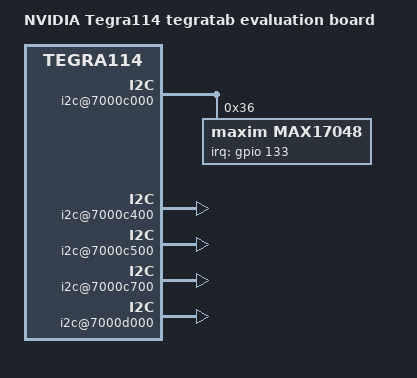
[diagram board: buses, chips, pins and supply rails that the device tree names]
/*
 * Copyright (c) 2013-2014, NVIDIA CORPORATION.  All rights reserved.
 *
 * This program is free software; you can redistribute it and/or modify it
 * under the terms and conditions of the GNU General Public License,
 * version 2, as published by the Free Software Foundation.
 *
 * This program is distributed in the hope it will be useful, but WITHOUT
 * ANY WARRANTY; without even the implied warranty of MERCHANTABILITY or
 * FITNESS FOR A PARTICULAR PURPOSE.  See the GNU General Public License for
 * more details.
 *
 * You should have received a copy of the GNU General Public License
 * along with this program.  If not, see <http://www.gnu.org/licenses/>.
 */

/include/ "tegra114.dtsi"

/ {
	model = "NVIDIA Tegra114 tegratab evaluation board";
	compatible = "nvidia,tegratab", "nvidia,tegra114";

	gpio@6000d000 {
		status = "okay";
	};

	interrupt-controller@50041000 {
		status = "okay";
	};

	pinmux {
		pinctrl-names = "default";
		pinctrl-0 = <&state_default>;

		state_default: pinmux {
			clk1_out_pw4 {
				nvidia,pins = "clk1_out_pw4";
				nvidia,function = "extperiph1";
				nvidia,pull = <0>;
				nvidia,tristate = <0>;
				nvidia,enable-input = <0>;
			};
			dap1_din_pn1 {
				nvidia,pins = "dap1_din_pn1";
				nvidia,function = "i2s0";
				nvidia,pull = <0>;
				nvidia,tristate = <1>;
				nvidia,enable-input = <1>;
			};
			dap1_dout_pn2 {
				nvidia,pins = "dap1_dout_pn2",
						"dap1_fs_pn0",
						"dap1_sclk_pn3";
				nvidia,function = "i2s0";
				nvidia,pull = <0>;
				nvidia,tristate = <0>;
				nvidia,enable-input = <1>;
			};
			dap2_din_pa4 {
				nvidia,pins = "dap2_din_pa4";
				nvidia,function = "i2s1";
				nvidia,pull = <0>;
				nvidia,tristate = <1>;
				nvidia,enable-input = <1>;
			};
			dap2_dout_pa5 {
				nvidia,pins = "dap2_dout_pa5",
						"dap2_fs_pa2",
						"dap2_sclk_pa3";
				nvidia,function = "i2s1";
				nvidia,pull = <0>;
				nvidia,tristate = <0>;
				nvidia,enable-input = <1>;
			};
			dap4_din_pp5 {
				nvidia,pins = "dap4_din_pp5",
						"dap4_dout_pp6",
						"dap4_fs_pp4",
						"dap4_sclk_pp7";
				nvidia,function = "i2s3";
				nvidia,pull = <0>;
				nvidia,tristate = <0>;
				nvidia,enable-input = <1>;
			};
			dvfs_pwm_px0 {
				nvidia,pins = "dvfs_pwm_px0",
						"dvfs_clk_px2";
				nvidia,function = "cldvfs";
				nvidia,pull = <0>;
				nvidia,tristate = <0>;
				nvidia,enable-input = <0>;
			};
			ulpi_clk_py0 {
				nvidia,pins = "ulpi_clk_py0",
						"ulpi_data0_po1",
						"ulpi_data1_po2",
						"ulpi_data2_po3",
						"ulpi_data3_po4",
						"ulpi_data4_po5",
						"ulpi_data5_po6",
						"ulpi_data6_po7",
						"ulpi_data7_po0";
				nvidia,function = "ulpi";
				nvidia,pull = <0>;
				nvidia,tristate = <0>;
				nvidia,enable-input = <1>;
			};
			ulpi_dir_py1 {
				nvidia,pins = "ulpi_dir_py1",
						"ulpi_nxt_py2";
				nvidia,function = "ulpi";
				nvidia,pull = <0>;
				nvidia,tristate = <1>;
				nvidia,enable-input = <1>;
			};
			ulpi_stp_py3 {
				nvidia,pins = "ulpi_stp_py3";
				nvidia,function = "ulpi";
				nvidia,pull = <0>;
				nvidia,tristate = <0>;
				nvidia,enable-input = <0>;
			};
			cam_i2c_scl_pbb1 {
				nvidia,pins = "cam_i2c_scl_pbb1",
						"cam_i2c_sda_pbb2";
				nvidia,function = "i2c3";
				nvidia,pull = <0>;
				nvidia,tristate = <0>;
				nvidia,enable-input = <1>;
				nvidia,lock = <0>;
				nvidia,open-drain = <0>;
			};
			cam_mclk_pcc0 {
				nvidia,pins = "cam_mclk_pcc0",
						"pbb0";
				nvidia,function = "vi_alt3";
				nvidia,pull = <0>;
				nvidia,tristate = <0>;
				nvidia,enable-input = <0>;
				nvidia,lock = <0>;
			};
			gen2_i2c_scl_pt5 {
				nvidia,pins = "gen2_i2c_scl_pt5",
						"gen2_i2c_sda_pt6";
				nvidia,function = "i2c2";
				nvidia,pull = <0>;
				nvidia,tristate = <0>;
				nvidia,enable-input = <1>;
				nvidia,lock = <0>;
				nvidia,open-drain = <0>;
			};
			gmi_a16_pj7 {
				nvidia,pins = "gmi_a16_pj7";
				nvidia,function = "uartd";
				nvidia,pull = <0>;
				nvidia,tristate = <0>;
				nvidia,enable-input = <0>;
			};
			gmi_a17_pb0 {
				nvidia,pins = "gmi_a17_pb0",
						"gmi_a18_pb1";
				nvidia,function = "uartd";
				nvidia,pull = <0>;
				nvidia,tristate = <1>;
				nvidia,enable-input = <1>;
			};
			gmi_a19_pk7 {
				nvidia,pins = "gmi_a19_pk7";
				nvidia,function = "uartd";
				nvidia,pull = <0>;
				nvidia,tristate = <0>;
				nvidia,enable-input = <0>;
			};
			gmi_ad5_pg5 {
				nvidia,pins = "gmi_ad5_pg5",
						"gmi_cs6_n_pi3",
						"gmi_wr_n_pi0";
				nvidia,function = "spi4";
				nvidia,pull = <0>;
				nvidia,tristate = <0>;
				nvidia,enable-input = <1>;
			};
			gmi_ad6_pg6 {
				nvidia,pins = "gmi_ad6_pg6",
						"gmi_ad7_pg7";
				nvidia,function = "spi4";
				nvidia,pull = <2>;
				nvidia,tristate = <0>;
				nvidia,enable-input = <1>;
			};
			gmi_ad12_ph4 {
				nvidia,pins = "gmi_ad12_ph4";
				nvidia,function = "rsvd4";
				nvidia,pull = <0>;
				nvidia,tristate = <0>;
				nvidia,enable-input = <0>;
			};
			gmi_ad9_ph1 {
				nvidia,pins = "gmi_ad9_ph1";
				nvidia,function = "pwm1";
				nvidia,pull = <0>;
				nvidia,tristate = <0>;
				nvidia,enable-input = <0>;
			};
			gmi_cs1_n_pj2 {
				nvidia,pins = "gmi_cs1_n_pj2",
						"gmi_oe_n_pi1";
				nvidia,function = "soc";
				nvidia,pull = <0>;
				nvidia,tristate = <1>;
				nvidia,enable-input = <1>;
			};
			clk2_out_pw5 {
				nvidia,pins = "clk2_out_pw5";
				nvidia,function = "extperiph2";
				nvidia,pull = <0>;
				nvidia,tristate = <0>;
				nvidia,enable-input = <0>;
			};
			sdmmc1_clk_pz0 {
				nvidia,pins = "sdmmc1_clk_pz0";
				nvidia,function = "sdmmc1";
				nvidia,pull = <0>;
				nvidia,tristate = <0>;
				nvidia,enable-input = <1>;
			};
			sdmmc1_cmd_pz1 {
				nvidia,pins = "sdmmc1_cmd_pz1",
						"sdmmc1_dat0_py7",
						"sdmmc1_dat1_py6",
						"sdmmc1_dat2_py5",
						"sdmmc1_dat3_py4";
				nvidia,function = "sdmmc1";
				nvidia,pull = <2>;
				nvidia,tristate = <0>;
				nvidia,enable-input = <1>;
			};
			sdmmc1_wp_n_pv3 {
				nvidia,pins = "sdmmc1_wp_n_pv3";
				nvidia,function = "spi4";
				nvidia,pull = <2>;
				nvidia,tristate = <0>;
				nvidia,enable-input = <0>;
			};
			sdmmc3_clk_pa6 {
				nvidia,pins = "sdmmc3_clk_pa6";
				nvidia,function = "sdmmc3";
				nvidia,pull = <0>;
				nvidia,tristate = <0>;
				nvidia,enable-input = <1>;
			};
			sdmmc3_cmd_pa7 {
				nvidia,pins = "sdmmc3_cmd_pa7",
						"sdmmc3_dat0_pb7",
						"sdmmc3_dat1_pb6",
						"sdmmc3_dat2_pb5",
						"sdmmc3_dat3_pb4",
						"kb_col4_pq4",
						"sdmmc3_clk_lb_out_pee4",
						"sdmmc3_clk_lb_in_pee5";
				nvidia,function = "sdmmc3";
				nvidia,pull = <2>;
				nvidia,tristate = <0>;
				nvidia,enable-input = <1>;
			};
			sdmmc4_clk_pcc4 {
				nvidia,pins = "sdmmc4_clk_pcc4";
				nvidia,function = "sdmmc4";
				nvidia,pull = <0>;
				nvidia,tristate = <0>;
				nvidia,enable-input = <1>;
			};
			sdmmc4_cmd_pt7 {
				nvidia,pins = "sdmmc4_cmd_pt7",
						"sdmmc4_dat0_paa0",
						"sdmmc4_dat1_paa1",
						"sdmmc4_dat2_paa2",
						"sdmmc4_dat3_paa3",
						"sdmmc4_dat4_paa4",
						"sdmmc4_dat5_paa5",
						"sdmmc4_dat6_paa6",
						"sdmmc4_dat7_paa7";
				nvidia,function = "sdmmc4";
				nvidia,pull = <2>;
				nvidia,tristate = <0>;
				nvidia,enable-input = <1>;
			};
			clk_32k_out_pa0 {
				nvidia,pins = "clk_32k_out_pa0";
				nvidia,function = "blink";
				nvidia,pull = <0>;
				nvidia,tristate = <0>;
				nvidia,enable-input = <0>;
			};
			kb_col0_pq0 {
				nvidia,pins = "kb_col0_pq0",
						"kb_col1_pq1",
						"kb_col2_pq2",
						"kb_row0_pr0",
						"kb_row1_pr1",
						"kb_row2_pr2";
				nvidia,function = "kbc";
				nvidia,pull = <2>;
				nvidia,tristate = <0>;
				nvidia,enable-input = <1>;
			};
			dap3_din_pp1 {
				nvidia,pins = "dap3_din_pp1",
						"dap3_sclk_pp3";
				nvidia,function = "displayb";
				nvidia,pull = <0>;
				nvidia,tristate = <1>;
				nvidia,enable-input = <0>;
			};
			pv0 {
				nvidia,pins = "pv0";
				nvidia,function = "rsvd4";
				nvidia,pull = <0>;
				nvidia,tristate = <1>;
				nvidia,enable-input = <0>;
			};
			kb_row7_pr7 {
				nvidia,pins = "kb_row7_pr7";
				nvidia,function = "rsvd2";
				nvidia,pull = <2>;
				nvidia,tristate = <0>;
				nvidia,enable-input = <1>;
			};
			kb_row10_ps2 {
				nvidia,pins = "kb_row10_ps2";
				nvidia,function = "uarta";
				nvidia,pull = <0>;
				nvidia,tristate = <1>;
				nvidia,enable-input = <1>;
			};
			kb_row9_ps1 {
				nvidia,pins = "kb_row9_ps1";
				nvidia,function = "uarta";
				nvidia,pull = <0>;
				nvidia,tristate = <0>;
				nvidia,enable-input = <0>;
			};
			pwr_i2c_scl_pz6 {
				nvidia,pins = "pwr_i2c_scl_pz6",
						"pwr_i2c_sda_pz7";
				nvidia,function = "i2cpwr";
				nvidia,pull = <0>;
				nvidia,tristate = <0>;
				nvidia,enable-input = <1>;
				nvidia,lock = <0>;
				nvidia,open-drain = <0>;
			};
			sys_clk_req_pz5 {
				nvidia,pins = "sys_clk_req_pz5";
				nvidia,function = "sysclk";
				nvidia,pull = <0>;
				nvidia,tristate = <0>;
				nvidia,enable-input = <0>;
			};
			core_pwr_req {
				nvidia,pins = "core_pwr_req";
				nvidia,function = "pwron";
				nvidia,pull = <0>;
				nvidia,tristate = <0>;
				nvidia,enable-input = <0>;
			};
			cpu_pwr_req {
				nvidia,pins = "cpu_pwr_req";
				nvidia,function = "cpu";
				nvidia,pull = <0>;
				nvidia,tristate = <0>;
				nvidia,enable-input = <0>;
			};
			pwr_int_n {
				nvidia,pins = "pwr_int_n";
				nvidia,function = "pmi";
				nvidia,pull = <0>;
				nvidia,tristate = <1>;
				nvidia,enable-input = <1>;
			};
			reset_out_n {
				nvidia,pins = "reset_out_n";
				nvidia,function = "reset_out_n";
				nvidia,pull = <0>;
				nvidia,tristate = <0>;
				nvidia,enable-input = <0>;
			};
			clk3_out_pee0 {
				nvidia,pins = "clk3_out_pee0";
				nvidia,function = "extperiph3";
				nvidia,pull = <0>;
				nvidia,tristate = <0>;
				nvidia,enable-input = <0>;
			};
			gen1_i2c_scl_pc4 {
				nvidia,pins = "gen1_i2c_scl_pc4",
						"gen1_i2c_sda_pc5";
				nvidia,function = "i2c1";
				nvidia,pull = <0>;
				nvidia,tristate = <0>;
				nvidia,enable-input = <1>;
				nvidia,lock = <0>;
				nvidia,open-drain = <0>;
			};
			uart2_cts_n_pj5 {
				nvidia,pins = "uart2_cts_n_pj5";
				nvidia,function = "uartb";
				nvidia,pull = <0>;
				nvidia,tristate = <1>;
				nvidia,enable-input = <1>;
			};
			uart2_rts_n_pj6 {
				nvidia,pins = "uart2_rts_n_pj6";
				nvidia,function = "uartb";
				nvidia,pull = <0>;
				nvidia,tristate = <0>;
				nvidia,enable-input = <0>;
			};
			uart2_rxd_pc3 {
				nvidia,pins = "uart2_rxd_pc3";
				nvidia,function = "irda";
				nvidia,pull = <0>;
				nvidia,tristate = <1>;
				nvidia,enable-input = <1>;
			};
			uart2_txd_pc2 {
				nvidia,pins = "uart2_txd_pc2";
				nvidia,function = "irda";
				nvidia,pull = <0>;
				nvidia,tristate = <0>;
				nvidia,enable-input = <0>;
			};
			uart3_cts_n_pa1 {
				nvidia,pins = "uart3_cts_n_pa1",
						"uart3_rxd_pw7";
				nvidia,function = "uartc";
				nvidia,pull = <0>;
				nvidia,tristate = <1>;
				nvidia,enable-input = <1>;
			};
			uart3_rts_n_pc0 {
				nvidia,pins = "uart3_rts_n_pc0",
						"uart3_txd_pw6";
				nvidia,function = "uartc";
				nvidia,pull = <0>;
				nvidia,tristate = <0>;
				nvidia,enable-input = <0>;
			};
			owr {
				nvidia,pins = "owr";
				nvidia,function = "owr";
				nvidia,pull = <0>;
				nvidia,tristate = <0>;
				nvidia,enable-input = <1>;
			};
			hdmi_cec_pee3 {
				nvidia,pins = "hdmi_cec_pee3";
				nvidia,function = "cec";
				nvidia,pull = <0>;
				nvidia,tristate = <0>;
				nvidia,enable-input = <1>;
				nvidia,lock = <0>;
				nvidia,open-drain = <0>;
			};
			ddc_scl_pv4 {
				nvidia,pins = "ddc_scl_pv4",
						"ddc_sda_pv5";
				nvidia,function = "i2c4";
				nvidia,pull = <0>;
				nvidia,tristate = <0>;
				nvidia,enable-input = <1>;
				nvidia,lock = <0>;
				nvidia,rcv-sel = <1>;
			};
			spdif_in_pk6 {
				nvidia,pins = "spdif_in_pk6";
				nvidia,function = "usb";
				nvidia,pull = <2>;
				nvidia,tristate = <0>;
				nvidia,enable-input = <1>;
				nvidia,lock = <0>;
			};
			usb_vbus_en0_pn4 {
				nvidia,pins = "usb_vbus_en0_pn4";
				nvidia,function = "usb";
				nvidia,pull = <2>;
				nvidia,tristate = <0>;
				nvidia,enable-input = <1>;
				nvidia,lock = <0>;
				nvidia,open-drain = <1>;
			};
			gpio_x6_aud_px6 {
				nvidia,pins = "gpio_x6_aud_px6";
				nvidia,function = "spi6";
				nvidia,pull = <2>;
				nvidia,tristate = <1>;
				nvidia,enable-input = <1>;
			};
			gpio_x4_aud_px4 {
				nvidia,pins = "gpio_x4_aud_px4",
						"gpio_x7_aud_px7";
				nvidia,function = "rsvd1";
				nvidia,pull = <1>;
				nvidia,tristate = <0>;
				nvidia,enable-input = <0>;
			};
			gpio_x5_aud_px5 {
				nvidia,pins = "gpio_x5_aud_px5";
				nvidia,function = "rsvd1";
				nvidia,pull = <2>;
				nvidia,tristate = <0>;
				nvidia,enable-input = <1>;
			};
			gpio_w2_aud_pw2 {
				nvidia,pins = "gpio_w2_aud_pw2";
				nvidia,function = "rsvd2";
				nvidia,pull = <2>;
				nvidia,tristate = <0>;
				nvidia,enable-input = <1>;
			};
			gpio_w3_aud_pw3 {
				nvidia,pins = "gpio_w3_aud_pw3";
				nvidia,function = "spi6";
				nvidia,pull = <2>;
				nvidia,tristate = <0>;
				nvidia,enable-input = <1>;
			};
			gpio_x1_aud_px1 {
				nvidia,pins = "gpio_x1_aud_px1";
				nvidia,function = "rsvd4";
				nvidia,pull = <1>;
				nvidia,tristate = <0>;
				nvidia,enable-input = <1>;
			};
			gpio_x3_aud_px3 {
				nvidia,pins = "gpio_x3_aud_px3";
				nvidia,function = "rsvd4";
				nvidia,pull = <2>;
				nvidia,tristate = <0>;
				nvidia,enable-input = <1>;
			};
			dap3_fs_pp0 {
				nvidia,pins = "dap3_fs_pp0";
				nvidia,function = "i2s2";
				nvidia,pull = <1>;
				nvidia,tristate = <0>;
				nvidia,enable-input = <0>;
			};
			dap3_dout_pp2 {
				nvidia,pins = "dap3_dout_pp2";
				nvidia,function = "i2s2";
				nvidia,pull = <1>;
				nvidia,tristate = <0>;
				nvidia,enable-input = <0>;
			};
			pv1 {
				nvidia,pins = "pv1";
				nvidia,function = "rsvd1";
				nvidia,pull = <0>;
				nvidia,tristate = <0>;
				nvidia,enable-input = <1>;
			};
			pbb3 {
				nvidia,pins = "pbb3",
						"pbb5",
						"pbb6",
						"pbb7";
				nvidia,function = "rsvd4";
				nvidia,pull = <1>;
				nvidia,tristate = <0>;
				nvidia,enable-input = <0>;
			};
			pcc1 {
				nvidia,pins = "pcc1",
						"pcc2";
				nvidia,function = "rsvd4";
				nvidia,pull = <1>;
				nvidia,tristate = <0>;
				nvidia,enable-input = <1>;
			};
			gmi_ad0_pg0 {
				nvidia,pins = "gmi_ad0_pg0",
						"gmi_ad1_pg1";
				nvidia,function = "gmi";
				nvidia,pull = <0>;
				nvidia,tristate = <0>;
				nvidia,enable-input = <0>;
			};
			gmi_ad10_ph2 {
				nvidia,pins = "gmi_ad10_ph2",
						"gmi_ad11_ph3",
						"gmi_ad13_ph5",
						"gmi_ad8_ph0",
						"gmi_clk_pk1";
				nvidia,function = "gmi";
				nvidia,pull = <1>;
				nvidia,tristate = <0>;
				nvidia,enable-input = <0>;
			};
			gmi_ad2_pg2 {
				nvidia,pins = "gmi_ad2_pg2",
						"gmi_ad3_pg3";
				nvidia,function = "gmi";
				nvidia,pull = <0>;
				nvidia,tristate = <0>;
				nvidia,enable-input = <1>;
			};
			gmi_adv_n_pk0 {
				nvidia,pins = "gmi_adv_n_pk0",
						"gmi_cs0_n_pj0",
						"gmi_cs2_n_pk3",
						"gmi_cs4_n_pk2",
						"gmi_cs7_n_pi6",
						"gmi_dqs_p_pj3",
						"gmi_iordy_pi5",
						"gmi_wp_n_pc7";
				nvidia,function = "gmi";
				nvidia,pull = <2>;
				nvidia,tristate = <0>;
				nvidia,enable-input = <1>;
			};
			gmi_cs3_n_pk4 {
				nvidia,pins = "gmi_cs3_n_pk4";
				nvidia,function = "gmi";
				nvidia,pull = <2>;
				nvidia,tristate = <0>;
				nvidia,enable-input = <0>;
			};
			clk2_req_pcc5 {
				nvidia,pins = "clk2_req_pcc5";
				nvidia,function = "rsvd4";
				nvidia,pull = <0>;
				nvidia,tristate = <0>;
				nvidia,enable-input = <0>;
			};
			kb_col3_pq3 {
				nvidia,pins = "kb_col3_pq3",
						"kb_col6_pq6",
						"kb_col7_pq7";
				nvidia,function = "kbc";
				nvidia,pull = <2>;
				nvidia,tristate = <0>;
				nvidia,enable-input = <0>;
			};
			kb_col5_pq5 {
				nvidia,pins = "kb_col5_pq5";
				nvidia,function = "kbc";
				nvidia,pull = <2>;
				nvidia,tristate = <0>;
				nvidia,enable-input = <1>;
			};
			kb_row3_pr3 {
				nvidia,pins = "kb_row3_pr3",
						"kb_row4_pr4",
						"kb_row6_pr6",
						"kb_row8_ps0";
				nvidia,function = "kbc";
				nvidia,pull = <1>;
				nvidia,tristate = <0>;
				nvidia,enable-input = <1>;
			};
			clk3_req_pee1 {
				nvidia,pins = "clk3_req_pee1";
				nvidia,function = "rsvd4";
				nvidia,pull = <0>;
				nvidia,tristate = <0>;
				nvidia,enable-input = <0>;
			};
			pu4 {
				nvidia,pins = "pu4";
				nvidia,function = "displayb";
				nvidia,pull = <0>;
				nvidia,tristate = <0>;
				nvidia,enable-input = <0>;
			};
			pu5 {
				nvidia,pins = "pu5",
						"pu6";
				nvidia,function = "displayb";
				nvidia,pull = <0>;
				nvidia,tristate = <0>;
				nvidia,enable-input = <1>;
			};
			hdmi_int_pn7 {
				nvidia,pins = "hdmi_int_pn7";
				nvidia,function = "rsvd1";
				nvidia,pull = <1>;
				nvidia,tristate = <0>;
				nvidia,enable-input = <1>;
			};
			clk1_req_pee2 {
				nvidia,pins = "clk1_req_pee2",
						"usb_vbus_en1_pn5";
				nvidia,function = "rsvd4";
				nvidia,pull = <1>;
				nvidia,tristate = <1>;
				nvidia,enable-input = <0>;
			};

			drive_sdio1 {
				nvidia,pins = "drive_sdio1";
				nvidia,high-speed-mode = <1>;
				nvidia,schmitt = <0>;
				nvidia,low-power-mode = <3>;
				nvidia,pull-down-strength = <36>;
				nvidia,pull-up-strength = <20>;
				nvidia,slew-rate-rising = <2>;
				nvidia,slew-rate-falling = <2>;
			};
			drive_sdio3 {
				nvidia,pins = "drive_sdio3";
				nvidia,high-speed-mode = <1>;
				nvidia,schmitt = <0>;
				nvidia,low-power-mode = <3>;
				nvidia,pull-down-strength = <22>;
				nvidia,pull-up-strength = <36>;
				nvidia,slew-rate-rising = <0>;
				nvidia,slew-rate-falling = <0>;
			};
			drive_gma {
				nvidia,pins = "drive_gma";
				nvidia,high-speed-mode = <1>;
				nvidia,schmitt = <0>;
				nvidia,low-power-mode = <3>;
				nvidia,pull-down-strength = <2>;
				nvidia,pull-up-strength = <1>;
				nvidia,slew-rate-rising = <0>;
				nvidia,slew-rate-falling = <0>;
				nvidia,drive-type = <1>;
			};
		};
	};

	host1x {
		compatible = "nvidia,tegra114-host1x", "simple-bus";
		reg = <0x50000000 0x00024000>;
		interrupts = <0 65 0x04   /* mpcore syncpt */
			      0 67 0x04>; /* mpcore general */

		#address-cells = <1>;
		#size-cells = <1>;

		ranges = <0x54000000 0x54000000 0x01000000>;

		vi {
			compatible = "nvidia,tegra114-vi";
			reg = <0x54080000 0x00040000>;
		};

		epp {
			compatible = "nvidia,tegra114-epp";
			reg = <0x540c0000 0x00040000>;
		};

		isp {
			compatible = "nvidia,tegra114-isp";
			reg = <0x54100000 0x00040000>;
		};

		gr2d {
			compatible = "nvidia,tegra114-gr2d";
			reg = <0x54140000 0x00040000>;
		};

		gr3d {
			compatible = "nvidia,tegra114-gr3d";
			reg = <0x54180000 0x00040000>;
		};

		dc@54200000 {
			compatible = "nvidia,tegra114-dc";
			reg = <0x54200000 0x00040000>;
			interrupts = <0 73 0x04>;
			status = "disabled";

			rgb {
				status = "disabled";
			};
		};

		dc@54240000 {
			compatible = "nvidia,tegra114-dc";
			reg = <0x54240000 0x00040000>;
			interrupts = <0 74 0x04>;
			status = "disabled";

			rgb {
				status = "disabled";
			};
		};

		hdmi {
			compatible = "nvidia,tegra114-hdmi";
			reg = <0x54280000 0x00040000>;
			interrupts = <0 75 0x04>;
			status = "disabled";
		};

		tvo {
			compatible = "nvidia,tegra114-tvo";
			reg = <0x542c0000 0x00040000>;
			interrupts = <0 76 0x04>;
			status = "disabled";
		};

		dsi {
			compatible = "nvidia,tegra114-dsi";
			reg = <0x54300000 0x00040000>;
			status = "disabled";
		};

		msenc {
			compatible = "nvidia,tegra114-msenc";
			reg = <0x544c0000 0x00040000>;
		};

		tsec {
			compatible = "nvidia,tegra114-tsec";
			reg = <0x54500000 0x00040000>;
		};
	};

	/* GEN1 */
	i2c@7000c000 {
		status = "okay";

		max17048@36 {
			compatible = "maxim,max17048";
			reg = <0x36>;
			interrupt-parent = <&gpio>;
			interrupts = <133 0x04>;	/* gpio PQ5 */
			alert-threshold = <1>;		/* 1% SOC */
			one-percent-alerts = <1>;
			valert-max = <5100>;		/* not use */
			valert-min = <3240>;		/* 3.24V */
			vreset-threshold = <2400>;
			vreset-disable = <1>;		/* not use */
			hib-threshold = <48>;		/* 9.984%/hr */
			hib-active-threshold = <128>;	/* 160mV */
			bits = <18>;
			rcomp = <57>;
			rcomp-seg = <0x0200>;
			soccheck-a = <119>;
			soccheck-b = <121>;
			ocvtest = <55952>;
			data-tbl = <0x98 0x80 0xB3 0x50 0xB7 0x90 0xB9 0x00
				0xBA 0x70 0xBC 0x10 0xBC 0x50 0xBC 0xA0
				0xBD 0x20 0xBE 0x30 0xBF 0x40 0xC2 0xF0
				0xC4 0x20 0xC7 0xE0 0xCB 0xF0 0xD0 0x90
				0x00 0x40 0x06 0x70 0x0E 0x50 0x12 0x00
				0x18 0xD0 0x33 0x10 0x31 0x40 0x35 0xD0
				0x18 0xD0 0x19 0x00 0x0B 0xF0 0x0C 0x10
				0x0D 0x10 0x07 0x90 0x08 0x00 0x08 0x00>;
		};
	};

	/* GEN2 */
	i2c@7000c400 {
		status = "okay";
	};

	/* CAM */
	i2c@7000c500 {
		status = "okay";
	};

	/* DDC */
	i2c@7000c700 {
		status = "okay";
	};

	/* PWR */
	i2c@7000d000 {
		status = "okay";
	};

	memory-controller@7001b000 {
		nvidia,use-ram-code = <1>;
		status = "okay";
		ram-code@0 { /* P1640_Micron_1GB_MT41K128M16-125 */
			#address-cells = <1>;
			#size-cells = <0>;
			nvidia,ram-code = <0>;
			emc-table@12750 {
				compatible = "nvidia,tegra11-emc-table";
				reg = <12750>;
				clock-frequency = <12750>;
				nvidia,revision = <0x42>;
				nvidia,emc-min-mv = <900>;
				nvidia,source = "pll_p";
				nvidia,src-sel-reg = <0x4400003e>;
				nvidia,burst-regs-num = <100>;
				nvidia,emc-trimmers-num = <30>;
				nvidia,burst-up-down-regs-num = <11>;
				nvidia,emc-registers = <0x00000000 0x00000003
						0x00000000 0x00000000 0x00000000 0x00000004
						0x0000000a 0x00000003 0x0000000b 0x00000000
						0x00000000 0x00000003 0x00000001 0x00000000
						0x00000005 0x0000000f 0x00000006 0x00010000
						0x00000000 0x00000004 0x0000000f 0x00000060
						0x00000000 0x00000018 0x00000002 0x00000002
						0x00000001 0x00000000 0x00000007 0x0000000f
						0x00000005 0x00000005 0x00000004 0x00000004
						0x00000004 0x00000004 0x00000000 0x00000004
						0x00000005 0x00000064 0x00000005 0x00000020
						0x00000000 0x0000aa88 0x002c00a0 0x00008000
						0x00058000 0x00058000 0x00058000 0x00058000
						0x00000000 0x00000000 0x00000000 0x00000000
						0x00000000 0x00000000 0x00000000 0x00000000
						0x001112a0 0x00000000 0x0000a11c 0x00000000
						0x77ffc085 0x81f1f108 0x03037504 0x0000003f
						0x0000003f 0x00000007 0x02000000 0x00000802
						0x00000000 0x00000042 0x000c000c 0x000c000c
						0x00000000 0x00000000 0x00000000 0x00000000
						0x800001c5 0x1f7df7df 0x0000001f 0x40040001
						0x8000003f 0x00000001 0x00000001 0x00000002
						0x00000000 0x00000001 0x00000001 0x00000002
						0x00000008 0x00000002 0x00000001 0x00000003
						0x00000006 0x06030102 0x000a0402 0x77e30303
						0x001f0000 0x00040320>;
				nvidia,emc-trimmers-0 = <0x00000000 0x00000006
						0x00000006 0x00000004 0x00000004 0x00058000
						0x00000009 0x00000000 0x0000000d 0x00249249
						0x20820800 0x00058000 0xa0f10f0f 0x00000000
						0x00000c0c 0x00000000 0x00000000 0x00000000
						0x00058000 0x00058000 0x00058000 0x00058000
						0x00058000 0x00058000 0x00000000 0x00000000
						0x00000000 0x00000000 0x00000000 0x00000000>;
				nvidia,emc-trimmers-1 = <0x00000000 0x00000006
						0x00000006 0x00000004 0x00000004 0x00058000
						0x00000009 0x00000000 0x0000000d 0x00249249
						0x20820800 0x00058000 0xa8f10f0f 0x00000000
						0x00000c0c 0x00000000 0x00000000 0x00000000
						0x00058000 0x00058000 0x00058000 0x00058000
						0x00058000 0x00058000 0x00000000 0x00000000
						0x00000000 0x00000000 0x00000000 0x00000000>;
				nvidia,emc-burst-up-down-regs = <0x00000007 0x00ff00ff
						0x00ff00ff 0x00ff00ff 0x000000ff 0x00ff00ff
						0x00ff00ff 0x000000ff 0x00ff00ff 0x00ff00ff
						0x00ff00ff 0x4E564441 0x04010700 0x02000400
						12750>;
				nvidia,emc-zcal-cnt-long = <0x00000042>;
				nvidia,emc-acal-interval = <0x001fffff>;
				nvidia,emc-cfg = <0x7324000e>;
				nvidia,emc-mode-reset = <0x80001221>;
				nvidia,emc-mode-1 = <0x80100003>;
				nvidia,emc-mode-2 = <0x80200008>;
				nvidia,emc-mode-4 = <0x00000000>;
				nvidia,emc-clock-latency-change = <57820>;
			};
			emc-table@20400 {
				compatible = "nvidia,tegra11-emc-table";
				reg = <20400>;
				clock-frequency = <20400>;
				nvidia,revision = <0x42>;
				nvidia,emc-min-mv = <900>;
				nvidia,source = "pll_p";
				nvidia,src-sel-reg = <0x44000026>;
				nvidia,burst-regs-num = <100>;
				nvidia,emc-trimmers-num = <30>;
				nvidia,burst-up-down-regs-num = <11>;
				nvidia,emc-registers = <0x00000000 0x00000003
						0x00000000 0x00000000 0x00000000 0x00000004
						0x0000000a 0x00000003 0x0000000b 0x00000000
						0x00000000 0x00000003 0x00000001 0x00000000
						0x00000005 0x0000000f 0x00000006 0x00010000
						0x00000000 0x00000004 0x0000000f 0x0000009a
						0x00000000 0x00000026 0x00000002 0x00000002
						0x00000001 0x00000000 0x00000007 0x0000000f
						0x00000005 0x00000005 0x00000004 0x00000004
						0x00000004 0x00000004 0x00000000 0x00000004
						0x00000005 0x000000a0 0x00000005 0x00000020
						0x00000000 0x0000aa88 0x002c00a0 0x00008000
						0x00058000 0x00058000 0x00058000 0x00058000
						0x00000000 0x00000000 0x00000000 0x00000000
						0x00000000 0x00000000 0x00000000 0x00000000
						0x001112a0 0x00000000 0x0000a11c 0x00000000
						0x77ffc085 0x81f1f108 0x03037504 0x0000003f
						0x0000003f 0x0000000b 0x02000000 0x00000802
						0x00000000 0x00000042 0x000c000c 0x000c000c
						0x00000000 0x00000000 0x00000000 0x00000000
						0x8000023a 0x1f7df7df 0x0000001f 0x40020001
						0x80000046 0x00000001 0x00000001 0x00000002
						0x00000000 0x00000001 0x00000001 0x00000002
						0x00000008 0x00000002 0x00000001 0x00000003
						0x00000006 0x06030102 0x000a0402 0x75430303
						0x001f0000 0x00040320>;
				nvidia,emc-trimmers-0 = <0x00000000 0x00000006
						0x00000006 0x00000004 0x00000004 0x00058000
						0x00000009 0x00000000 0x0000000d 0x00249249
						0x20820800 0x00058000 0xa0f10f0f 0x00000000
						0x00000c0c 0x00000000 0x00000000 0x00000000
						0x00058000 0x00058000 0x00058000 0x00058000
						0x00058000 0x00058000 0x00000000 0x00000000
						0x00000000 0x00000000 0x00000000 0x00000000>;
				nvidia,emc-trimmers-1 = <0x00000000 0x00000006
						0x00000006 0x00000004 0x00000004 0x00058000
						0x00000009 0x00000000 0x0000000d 0x00249249
						0x20820800 0x00058000 0xa8f10f0f 0x00000000
						0x00000c0c 0x00000000 0x00000000 0x00000000
						0x00058000 0x00058000 0x00058000 0x00058000
						0x00058000 0x00058000 0x00000000 0x00000000
						0x00000000 0x00000000 0x00000000 0x00000000>;
				nvidia,emc-burst-up-down-regs = <0x0000000a 0x00ff00ff
						0x00ff00ff 0x00ff00ff 0x000000ff 0x00ff00ff
						0x00ff00ff 0x000000ff 0x00ff00ff 0x00ff00ff
						0x00ff00ff 0x4E564441 0x04010700 0x02000400
						20400>;
				nvidia,emc-zcal-cnt-long = <0x00000042>;
				nvidia,emc-acal-interval = <0x001fffff>;
				nvidia,emc-cfg = <0x7324000e>;
				nvidia,emc-mode-reset = <0x80001221>;
				nvidia,emc-mode-1 = <0x80100003>;
				nvidia,emc-mode-2 = <0x80200008>;
				nvidia,emc-mode-4 = <0x00000000>;
				nvidia,emc-clock-latency-change = <35610>;
			};
			emc-table@40800 {
				compatible = "nvidia,tegra11-emc-table";
				reg = <40800>;
				clock-frequency = <40800>;
				nvidia,revision = <0x42>;
				nvidia,emc-min-mv = <900>;
				nvidia,source = "pll_p";
				nvidia,src-sel-reg = <0x44000012>;
				nvidia,burst-regs-num = <100>;
				nvidia,emc-trimmers-num = <30>;
				nvidia,burst-up-down-regs-num = <11>;
				nvidia,emc-registers = <0x00000001 0x00000006
						0x00000000 0x00000001 0x00000000 0x00000004
						0x0000000a 0x00000003 0x0000000b 0x00000000
						0x00000000 0x00000003 0x00000001 0x00000000
						0x00000005 0x0000000f 0x00000006 0x00010000
						0x00000000 0x00000004 0x0000000f 0x00000134
						0x00000000 0x0000004d 0x00000002 0x00000002
						0x00000001 0x00000000 0x00000007 0x0000000f
						0x00000007 0x00000007 0x00000004 0x00000004
						0x00000004 0x00000004 0x00000000 0x00000004
						0x00000005 0x0000013f 0x00000005 0x00000020
						0x00000000 0x0000aa88 0x002c00a0 0x00008000
						0x00058000 0x00058000 0x00058000 0x00058000
						0x00000000 0x00000000 0x00000000 0x00000000
						0x00000000 0x00000000 0x00000000 0x00000000
						0x001112a0 0x00000000 0x0000a11c 0x00000000
						0x77ffc085 0x81f1f108 0x03037504 0x0000003f
						0x0000003f 0x00000015 0x02000000 0x00000802
						0x00000000 0x00000042 0x000c000c 0x000c000c
						0x00000000 0x00000000 0x00000000 0x00000000
						0x80000370 0x1f7df7df 0x0000001f 0xa0000001
						0x8000005b 0x00000001 0x00000001 0x00000002
						0x00000000 0x00000001 0x00000001 0x00000002
						0x00000008 0x00000002 0x00000001 0x00000003
						0x00000006 0x06030102 0x000a0402 0x73630303
						0x001f0000 0x00040320>;
				nvidia,emc-trimmers-0 = <0x00000000 0x00000006
						0x00000006 0x00000004 0x00000004 0x00058000
						0x00000009 0x00000000 0x0000000d 0x00249249
						0x20820800 0x00058000 0xa0f10f0f 0x00000000
						0x00000c0c 0x00000000 0x00000000 0x00000000
						0x00058000 0x00058000 0x00058000 0x00058000
						0x00058000 0x00058000 0x00000000 0x00000000
						0x00000000 0x00000000 0x00000000 0x00000000>;
				nvidia,emc-trimmers-1 = <0x00000000 0x00000006
						0x00000006 0x00000004 0x00000004 0x00058000
						0x00000009 0x00000000 0x0000000d 0x00249249
						0x20820800 0x00058000 0xa8f10f0f 0x00000000
						0x00000c0c 0x00000000 0x00000000 0x00000000
						0x00058000 0x00058000 0x00058000 0x00058000
						0x00058000 0x00058000 0x00000000 0x00000000
						0x00000000 0x00000000 0x00000000 0x00000000>;
				nvidia,emc-burst-up-down-regs = <0x00000015 0x00b000b0
						0x00b000c4 0x00d700eb 0x000000eb 0x00eb00eb
						0x00ff00eb 0x000000ff 0x00ff00ff 0x00ff00ff
						0x00ff00ff 0x4E564441 0x04010700 0x02000400
						40800>;
				nvidia,emc-zcal-cnt-long = <0x00000042>;
				nvidia,emc-acal-interval = <0x001fffff>;
				nvidia,emc-cfg = <0x7324000e>;
				nvidia,emc-mode-reset = <0x80001221>;
				nvidia,emc-mode-1 = <0x80100003>;
				nvidia,emc-mode-2 = <0x80200008>;
				nvidia,emc-mode-4 = <0x00000000>;
				nvidia,emc-clock-latency-change = <20850>;
			};
			emc-table@68000 {
				compatible = "nvidia,tegra11-emc-table";
				reg = <68000>;
				clock-frequency = <68000>;
				nvidia,revision = <0x42>;
				nvidia,emc-min-mv = <900>;
				nvidia,source = "pll_p";
				nvidia,src-sel-reg = <0x4400000a>;
				nvidia,burst-regs-num = <100>;
				nvidia,emc-trimmers-num = <30>;
				nvidia,burst-up-down-regs-num = <11>;
				nvidia,emc-registers = <0x00000003 0x0000000a
						0x00000000 0x00000002 0x00000000 0x00000004
						0x0000000a 0x00000003 0x0000000b 0x00000000
						0x00000000 0x00000003 0x00000001 0x00000000
						0x00000005 0x0000000f 0x00000006 0x00010000
						0x00000000 0x00000004 0x0000000f 0x00000202
						0x00000000 0x00000080 0x00000002 0x00000002
						0x00000001 0x00000000 0x00000008 0x0000000f
						0x0000000c 0x0000000c 0x00000004 0x00000004
						0x00000004 0x00000004 0x00000000 0x00000004
						0x00000005 0x00000213 0x00000005 0x00000020
						0x00000000 0x0000aa88 0x002c00a0 0x00008000
						0x00058000 0x00058000 0x00058000 0x00058000
						0x00000000 0x00000000 0x00000000 0x00000000
						0x00000000 0x00000000 0x00000000 0x00000000
						0x001112a0 0x00000000 0x0000a11c 0x00000000
						0x77ffc085 0x81f1f108 0x03037504 0x0000003f
						0x0000003f 0x00000022 0x02000000 0x00000802
						0x00000000 0x00000042 0x000c000c 0x000c000c
						0x00000000 0x00000000 0x00000000 0x00000000
						0x8000050e 0x1f7df7df 0x0000001f 0x00000001
						0x80000076 0x00000001 0x00000001 0x00000002
						0x00000000 0x00000001 0x00000001 0x00000002
						0x00000008 0x00000002 0x00000001 0x00000003
						0x00000006 0x06030102 0x000a0402 0x72c30403
						0x001f0000 0x00040320>;
				nvidia,emc-trimmers-0 = <0x00000000 0x00000006
						0x00000006 0x00000004 0x00000004 0x00058000
						0x00000009 0x00000000 0x0000000d 0x00249249
						0x20820800 0x00058000 0xa0f10f0f 0x00000000
						0x00000c0c 0x00000000 0x00000000 0x00000000
						0x00058000 0x00058000 0x00058000 0x00058000
						0x00058000 0x00058000 0x00000000 0x00000000
						0x00000000 0x00000000 0x00000000 0x00000000>;
				nvidia,emc-trimmers-1 = <0x00000000 0x00000006
						0x00000006 0x00000004 0x00000004 0x00058000
						0x00000009 0x00000000 0x0000000d 0x00249249
						0x20820800 0x00058000 0xa8f10f0f 0x00000000
						0x00000c0c 0x00000000 0x00000000 0x00000000
						0x00058000 0x00058000 0x00058000 0x00058000
						0x00058000 0x00058000 0x00000000 0x00000000
						0x00000000 0x00000000 0x00000000 0x00000000>;
				nvidia,emc-burst-up-down-regs = <0x00000023 0x00690069
						0x00690075 0x0081008d 0x0000008d 0x008d008d
						0x00bc008d 0x000000bc 0x00bc00bc 0x00ff00ff
						0x00ff00ff 0x4E564441 0x04010700 0x02000400
						68000>;
				nvidia,emc-zcal-cnt-long = <0x00000042>;
				nvidia,emc-acal-interval = <0x001fffff>;
				nvidia,emc-cfg = <0x7324000e>;
				nvidia,emc-mode-reset = <0x80001221>;
				nvidia,emc-mode-1 = <0x80100003>;
				nvidia,emc-mode-2 = <0x80200008>;
				nvidia,emc-mode-4 = <0x00000000>;
				nvidia,emc-clock-latency-change = <10720>;
			};
			emc-table@102000 {
				compatible = "nvidia,tegra11-emc-table";
				reg = <102000>;
				clock-frequency = <102000>;
				nvidia,revision = <0x42>;
				nvidia,emc-min-mv = <900>;
				nvidia,source = "pll_p";
				nvidia,src-sel-reg = <0x44000006>;
				nvidia,burst-regs-num = <100>;
				nvidia,emc-trimmers-num = <30>;
				nvidia,burst-up-down-regs-num = <11>;
				nvidia,emc-registers = <0x00000004 0x00000010
						0x00000000 0x00000003 0x00000001 0x00000004
						0x0000000a 0x00000003 0x0000000b 0x00000001
						0x00000001 0x00000003 0x00000001 0x00000000
						0x00000005 0x0000000f 0x00000006 0x00010000
						0x00000000 0x00000004 0x0000000f 0x00000303
						0x00000000 0x000000c0 0x00000002 0x00000002
						0x00000001 0x00000000 0x0000000d 0x0000000f
						0x00000012 0x00000012 0x00000004 0x00000004
						0x00000004 0x00000005 0x00000000 0x00000004
						0x00000005 0x0000031c 0x00000005 0x00000020
						0x00000000 0x0000aa88 0x002c00a0 0x00008000
						0x00058000 0x00058000 0x00058000 0x00058000
						0x00000000 0x00000000 0x00000000 0x00000000
						0x00000000 0x00000000 0x00000000 0x00000000
						0x001112a0 0x00000000 0x0000a11c 0x00000000
						0x77ffc085 0x81f1f108 0x03037504 0x0000003f
						0x0000003f 0x00000033 0x02000000 0x00000802
						0x00000000 0x00000042 0x000c000c 0x000c000c
						0x00000000 0x00000000 0x00000000 0x00000000
						0x80000713 0x1f7df7df 0x0000001f 0x08000001
						0x80000098 0x00000001 0x00000001 0x00000003
						0x00000000 0x00000002 0x00000001 0x00000002
						0x00000008 0x00000002 0x00000001 0x00000003
						0x00000006 0x06030102 0x000a0403 0x72830504
						0x001f0000 0x00040320>;
				nvidia,emc-trimmers-0 = <0x00000000 0x00000006
						0x00000006 0x00000004 0x00000004 0x00058000
						0x00000009 0x00000000 0x0000000d 0x00249249
						0x20820800 0x00058000 0xa0f10f0f 0x00000000
						0x00000c0c 0x00000000 0x00000000 0x00000000
						0x00058000 0x00058000 0x00058000 0x00058000
						0x00058000 0x00058000 0x00000000 0x00000000
						0x00000000 0x00000000 0x00000000 0x00000000>;
				nvidia,emc-trimmers-1 = <0x00000000 0x00000006
						0x00000006 0x00000004 0x00000004 0x00058000
						0x00000009 0x00000000 0x0000000d 0x00249249
						0x20820800 0x00058000 0xa8f10f0f 0x00000000
						0x00000c0c 0x00000000 0x00000000 0x00000000
						0x00058000 0x00058000 0x00058000 0x00058000
						0x00058000 0x00058000 0x00000000 0x00000000
						0x00000000 0x00000000 0x00000000 0x00000000>;
				nvidia,emc-burst-up-down-regs = <0x00000034 0x00460046
						0x0046004e 0x0056005e 0x0000005e 0x005e005e
						0x007d005e 0x0000007d 0x007d007d 0x00ff00ff
						0x00ff00ff 0x4E564441 0x04010700 0x02000400
						102000>;
				nvidia,emc-zcal-cnt-long = <0x00000042>;
				nvidia,emc-acal-interval = <0x001fffff>;
				nvidia,emc-cfg = <0x7324000e>;
				nvidia,emc-mode-reset = <0x80001221>;
				nvidia,emc-mode-1 = <0x80100003>;
				nvidia,emc-mode-2 = <0x80200008>;
				nvidia,emc-mode-4 = <0x00000000>;
				nvidia,emc-clock-latency-change = <6890>;
			};
			emc-table@204000 {
				compatible = "nvidia,tegra11-emc-table";
				reg = <204000>;
				clock-frequency = <204000>;
				nvidia,revision = <0x42>;
				nvidia,emc-min-mv = <900>;
				nvidia,source = "pll_p";
				nvidia,src-sel-reg = <0x44000002>;
				nvidia,burst-regs-num = <100>;
				nvidia,emc-trimmers-num = <30>;
				nvidia,burst-up-down-regs-num = <11>;
				nvidia,emc-registers = <0x00000009 0x00000020
						0x00000000 0x00000007 0x00000002 0x00000004
						0x0000000a 0x00000003 0x0000000b 0x00000002
						0x00000002 0x00000003 0x00000001 0x00000000
						0x00000005 0x0000000f 0x00000006 0x00010000
						0x00000000 0x00000004 0x0000000f 0x00000607
						0x00000000 0x00000181 0x00000002 0x00000002
						0x00000001 0x00000000 0x0000001d 0x0000000f
						0x00000023 0x00000023 0x00000004 0x00000004
						0x00000004 0x00000009 0x00000000 0x00000004
						0x00000005 0x00000638 0x00000006 0x00000020
						0x00000000 0x0000aa88 0x002c00a0 0x00008000
						0x00058000 0x00058000 0x00058000 0x00058000
						0x00000000 0x00000000 0x00000000 0x00000000
						0x00000000 0x00000000 0x00000000 0x00000000
						0x001112a0 0x00000000 0x0000a11c 0x00000000
						0x77ffc085 0x81f1f108 0x03037504 0x0000003f
						0x0000003f 0x00000000 0x02000000 0x00000802
						0x00020000 0x00000100 0x000c000c 0x000c000c
						0x00000000 0x00000000 0x00000000 0x00000000
						0x80000d22 0x1f7df7df 0x0000001f 0x01000003
						0x800000fe 0x00000001 0x00000001 0x00000005
						0x00000002 0x00000004 0x00000001 0x00000002
						0x00000008 0x00000002 0x00000001 0x00000003
						0x00000006 0x06030102 0x000a0405 0x72440a06
						0x001f0000 0x00040320>;
				nvidia,emc-trimmers-0 = <0x00000000 0x00000004
						0x00000007 0x00000004 0x00000004 0x00058000
						0x00000009 0x00000000 0x0000000d 0x00249249
						0x20820800 0x00058000 0xa0f10f0f 0x00000000
						0x00000c0c 0x00000000 0x00000000 0x00000000
						0x00058000 0x00058000 0x00058000 0x00058000
						0x00058000 0x00058000 0x00000000 0x00000000
						0x00000000 0x00000000 0x00000000 0x00000000>;
				nvidia,emc-trimmers-1 = <0x00000000 0x00000004
						0x00000007 0x00000004 0x00000004 0x00058000
						0x00000009 0x00000000 0x0000000d 0x00249249
						0x20820800 0x00058000 0xa8f10f0f 0x00000000
						0x00000c0c 0x00000000 0x00000000 0x00000000
						0x00058000 0x00058000 0x00058000 0x00058000
						0x00058000 0x00058000 0x00000000 0x00000000
						0x00000000 0x00000000 0x00000000 0x00000000>;
				nvidia,emc-burst-up-down-regs = <0x00000068 0x00230023
						0x00230027 0x002b002f 0x0000002f 0x002f002f
						0x003e002f 0x0000003e 0x003e003e 0x00ff00c8
						0x00ff00ff 0x4E564441 0x04010700 0x02000400
						204000>;
				nvidia,emc-zcal-cnt-long = <0x00000042>;
				nvidia,emc-acal-interval = <0x001fffff>;
				nvidia,emc-cfg = <0x7320000e>;
				nvidia,emc-mode-reset = <0x80001221>;
				nvidia,emc-mode-1 = <0x80100003>;
				nvidia,emc-mode-2 = <0x80200008>;
				nvidia,emc-mode-4 = <0x00000000>;
				nvidia,emc-clock-latency-change = <3420>;
			};
			emc-table@312000 {
				compatible = "nvidia,tegra11-emc-table";
				reg = <312000>;
				clock-frequency = <312000>;
				nvidia,revision = <0x42>;
				nvidia,emc-min-mv = <1000>;
				nvidia,source = "pll_c";
				nvidia,src-sel-reg = <0x24000002>;
				nvidia,burst-regs-num = <100>;
				nvidia,emc-trimmers-num = <30>;
				nvidia,burst-up-down-regs-num = <11>;
				nvidia,emc-registers = <0x0000000e 0x00000030
						0x00000000 0x00000009 0x00000003 0x00000004
						0x00000008 0x00000002 0x00000009 0x00000003
						0x00000003 0x00000002 0x00000001 0x00000000
						0x00000004 0x0000000f 0x00000006 0x00010000
						0x00000000 0x00000004 0x0000000f 0x00000941
						0x00000000 0x00000250 0x00000001 0x00000008
						0x00000001 0x00000000 0x0000002e 0x0000000e
						0x00000036 0x00000200 0x00000004 0x00000004
						0x00000004 0x0000000d 0x00000000 0x00000004
						0x00000005 0x00000982 0x00000000 0x00000020
						0x00000000 0x00005088 0x002c00a0 0x00008000
						0x0002c000 0x0002c000 0x0002c000 0x0002c000
						0x00008000 0x00008000 0x00008000 0x00008000
						0x00000000 0x00000000 0x00000000 0x00000000
						0x001112a0 0x00000000 0x0001013d 0x00000000
						0x77ffc085 0x81f1f108 0x03037504 0x00000000
						0x0000003f 0x00000000 0x02000000 0x00000802
						0x00020000 0x00000100 0x0190000c 0x0190000c
						0x00000000 0x00000000 0x00000000 0x00000000
						0x8000138d 0x1f7df7df 0x0000001f 0x0b000004
						0x8000016a 0x00000001 0x00000002 0x00000007
						0x00000004 0x00000006 0x00000001 0x00000002
						0x00000007 0x00000002 0x00000002 0x00000004
						0x00000006 0x06040202 0x000b0607 0x76e50f08
						0x001f0000 0x00040320>;
				nvidia,emc-trimmers-0 = <0x00000000 0x00000004
						0x00000006 0x00000005 0x00000004 0x0002c000
						0x0000000b 0x00008000 0x0000000d 0x00249249
						0x20820800 0x00030000 0xa0f10f0f 0x00000000
						0x00000b0b 0x00000000 0x00000000 0x00000000
						0x0002c000 0x0002c000 0x0002c000 0x00030000
						0x00030000 0x00030000 0x00000000 0x00000000
						0x00000000 0x00008000 0x00008000 0x00008000>;
				nvidia,emc-trimmers-1 = <0x00000000 0x00000004
						0x00000006 0x00000005 0x00000004 0x0002c000
						0x0000000b 0x00008000 0x0000000d 0x00249249
						0x20820800 0x00030000 0xa8f10f0f 0x00000000
						0x00000a0a 0x00000000 0x00000000 0x00000000
						0x0002c000 0x0002c000 0x0002c000 0x00030000
						0x00030000 0x00030000 0x00000000 0x00000000
						0x00000000 0x00008000 0x00008000 0x00008000>;
				nvidia,emc-burst-up-down-regs = <0x000000a0 0x00170017
						0x00170019 0x001c001e 0x0000001e 0x001e001e
						0x0029001e 0x00000029 0x00290029 0x00ff0082
						0x00ff00ff 0x4E564441 0x04010700 0x02000400
						312000>;
				nvidia,emc-zcal-cnt-long = <0x00000042>;
				nvidia,emc-acal-interval = <0x001fffff>;
				nvidia,emc-cfg = <0x5300000e>;
				nvidia,emc-mode-reset = <0x80000321>;
				nvidia,emc-mode-1 = <0x80100002>;
				nvidia,emc-mode-2 = <0x80200000>;
				nvidia,emc-mode-4 = <0x00000000>;
				nvidia,emc-clock-latency-change = <2180>;
			};
			emc-table@408000 {
				compatible = "nvidia,tegra11-emc-table";
				reg = <408000>;
				clock-frequency = <408000>;
				nvidia,revision = <0x42>;
				nvidia,emc-min-mv = <1000>;
				nvidia,source = "pll_p";
				nvidia,src-sel-reg = <0x44000000>;
				nvidia,burst-regs-num = <100>;
				nvidia,emc-trimmers-num = <30>;
				nvidia,burst-up-down-regs-num = <11>;
				nvidia,emc-registers = <0x00000012 0x00000040
						0x00000000 0x0000000d 0x00000004 0x00000005
						0x00000009 0x00000002 0x0000000c 0x00000004
						0x00000004 0x00000002 0x00000001 0x00000000
						0x00000004 0x0000000f 0x00000006 0x00010000
						0x00000000 0x00000004 0x00000010 0x00000c2e
						0x00000000 0x0000030b 0x00000001 0x00000008
						0x00000001 0x00000000 0x0000003d 0x00000011
						0x00000046 0x00000200 0x00000004 0x00000004
						0x00000004 0x00000011 0x00000000 0x00000004
						0x00000005 0x00000c6f 0x00000000 0x00000020
						0x00000000 0x00005088 0x002c0080 0x00008000
						0x00020000 0x00020000 0x00020000 0x00020000
						0x00010000 0x00010000 0x00010000 0x00010000
						0x00000000 0x00000000 0x00000000 0x00000000
						0x001112a0 0x00000000 0x0001013d 0x00000000
						0x77ffc085 0x81f1f108 0x03037504 0x00000000
						0x0000003f 0x00000000 0x02000000 0x00000802
						0x00020000 0x00000100 0x0181000c 0x0181000c
						0x00000000 0x00000000 0x00000000 0x00000000
						0x80001941 0x1f7df7df 0x0000001f 0x02000006
						0x80000190 0x00000001 0x00000002 0x0000000a
						0x00000006 0x00000008 0x00000001 0x00000002
						0x00000009 0x00000002 0x00000002 0x00000004
						0x00000006 0x06040202 0x000e070a 0x7547130b
						0x001f0000 0x00040320>;
				nvidia,emc-trimmers-0 = <0x00000000 0x00000004
						0x00000006 0x00000005 0x00000004 0x00020000
						0x0000000c 0x00010000 0x0000000e 0x00249249
						0x20820800 0x00020000 0xa0f10f0f 0x00000000
						0x00000606 0x00000000 0x00000000 0x00000000
						0x00020000 0x00020000 0x00020000 0x00020000
						0x00020000 0x00020000 0x00000000 0x00000000
						0x00000000 0x00010000 0x00010000 0x00010000>;
				nvidia,emc-trimmers-1 = <0x00000000 0x00000004
						0x00000006 0x00000005 0x00000004 0x00020000
						0x0000000c 0x00010000 0x0000000e 0x00249249
						0x20820800 0x00020000 0xa8f10f0f 0x00000000
						0x00000606 0x00000000 0x00000000 0x00000000
						0x00020000 0x00020000 0x00020000 0x00020000
						0x00020000 0x00020000 0x00000000 0x00000000
						0x00000000 0x00010000 0x00010000 0x00010000>;
				nvidia,emc-burst-up-down-regs = <0x000000d1 0x00110011
						0x00110013 0x00150017 0x00000017 0x00170017
						0x001f0017 0x0000001f 0x001f001f 0x00d30064
						0x00d300d3 0x4E564441 0x04010700 0x02000400
						408000>;
				nvidia,emc-zcal-cnt-long = <0x00000042>;
				nvidia,emc-acal-interval = <0x001fffff>;
				nvidia,emc-cfg = <0x53000006>;
				nvidia,emc-mode-reset = <0x80000731>;
				nvidia,emc-mode-1 = <0x80100002>;
				nvidia,emc-mode-2 = <0x80200008>;
				nvidia,emc-mode-4 = <0x00000000>;
				nvidia,emc-clock-latency-change = <1750>;
			};
			emc-table@624000 {
				compatible = "nvidia,tegra11-emc-table";
				reg = <624000>;
				clock-frequency = <624000>;
				nvidia,revision = <0x42>;
				nvidia,emc-min-mv = <1100>;
				nvidia,source = "pll_c";
				nvidia,src-sel-reg = <0x24000000>;
				nvidia,burst-regs-num = <100>;
				nvidia,emc-trimmers-num = <30>;
				nvidia,burst-up-down-regs-num = <11>;
				nvidia,emc-registers = <0x0000001d 0x00000062
						0x00000000 0x00000014 0x00000007 0x00000007
						0x0000000b 0x00000003 0x00000010 0x00000007
						0x00000007 0x00000003 0x00000001 0x00000000
						0x00000005 0x0000000f 0x0000000a 0x00010000
						0x00000000 0x00000007 0x00000014 0x000012c3
						0x00000000 0x000004b0 0x00000002 0x0000000d
						0x00000001 0x00000000 0x0000005d 0x00000015
						0x0000006b 0x00000200 0x00000005 0x00000005
						0x00000005 0x00000019 0x00000000 0x00000006
						0x00000007 0x00001304 0x00000009 0x80000000
						0x00000000 0x0000ba88 0xf00d0191 0x00008000
						0x00000006 0x00000006 0x00000006 0x00000006
						0x00008000 0x00008000 0x00008000 0x00008000
						0x00000000 0x00000000 0x00000000 0x00000000
						0x001112a0 0x00000000 0x0000013d 0x00000000
						0x77ffc085 0x81f1f108 0x07077504 0x00000000
						0x0000003f 0x00000000 0x02000000 0x00000802
						0x00020000 0x00000100 0x0161000c 0x0161000c
						0x00000000 0x00000000 0x00000000 0x00000000
						0x80002617 0x1f7df7df 0x0000001f 0x06000009
						0x80000190 0x00000003 0x00000004 0x0000000f
						0x00000009 0x0000000c 0x00000002 0x00000003
						0x0000000b 0x00000002 0x00000002 0x00000005
						0x00000007 0x07050202 0x00130b0f 0x736a1d10
						0x001f0000 0x00040320>;
				nvidia,emc-trimmers-0 = <0x00000000 0x00000006
						0x00000009 0x00000008 0x00000004 0x00000006
						0x0000000c 0x00008000 0x00000012 0x0028a28a
						0x20820800 0x00000009 0xa0f10f0f 0x00000000
						0x00000b0b 0x00000000 0x00000000 0x00000000
						0x00000006 0x00000006 0x00000006 0x00000009
						0x00000009 0x00000009 0x00000000 0x00000000
						0x00000000 0x00008000 0x00008000 0x00008000>;
				nvidia,emc-trimmers-1 = <0x00000000 0x00000006
						0x00000009 0x00000008 0x00000004 0x00000006
						0x0000000c 0x00008000 0x00000012 0x0028a28a
						0x20820800 0x00000009 0xa8f10f0f 0x00000000
						0x00000b0b 0x00000000 0x00000000 0x00000000
						0x00000006 0x00000006 0x00000006 0x00000009
						0x00000009 0x00000009 0x00000000 0x00000000
						0x00000000 0x00008000 0x00008000 0x00008000>;
				nvidia,emc-burst-up-down-regs = <0x0000013f 0x000b000b
						0x000b000c 0x000e000f 0x0000000f 0x000f000f
						0x0014000f 0x00000014 0x00140014 0x008a0041
						0x008a008a 0x4E564441 0x04010700 0x02000400
						624000>;
				nvidia,emc-zcal-cnt-long = <0x00000042>;
				nvidia,emc-acal-interval = <0x001fffff>;
				nvidia,emc-cfg = <0x53200000>;
				nvidia,emc-mode-reset = <0x80000b61>;
				nvidia,emc-mode-1 = <0x80100002>;
				nvidia,emc-mode-2 = <0x80200410>;
				nvidia,emc-mode-4 = <0x00000000>;
				nvidia,emc-clock-latency-change = <1290>;
			};
			emc-table@792000 {
				compatible = "nvidia,tegra11-emc-table";
				reg = <792000>;
				clock-frequency = <792000>;
				nvidia,revision = <0x42>;
				nvidia,emc-min-mv = <1100>;
				nvidia,source = "pll_m";
				nvidia,src-sel-reg = <0x84000000>;
				nvidia,burst-regs-num = <100>;
				nvidia,emc-trimmers-num = <30>;
				nvidia,burst-up-down-regs-num = <11>;
				nvidia,emc-registers = <0x00000025 0x0000007d
						0x00000000 0x0000001a 0x00000009 0x00000008
						0x0000000d 0x00000004 0x00000013 0x00000009
						0x00000009 0x00000004 0x00000001 0x00000000
						0x00000006 0x0000000f 0x0000000b 0x00010000
						0x00000000 0x00000008 0x00000016 0x000017e1
						0x00000000 0x000005f8 0x00000003 0x00000011
						0x00000001 0x00000000 0x00000076 0x00000018
						0x00000087 0x00000200 0x00000005 0x00000005
						0x00000005 0x00000020 0x00000000 0x00000007
						0x00000008 0x00001822 0x00000000 0x80000000
						0x00000000 0x00005088 0xf0070191 0x00008000
						0x00000008 0x00000008 0x00000008 0x00000008
						0x00000000 0x00000000 0x00000000 0x00000000
						0x00000000 0x00000000 0x00000000 0x00000000
						0x001112a0 0x00000000 0x0000013d 0x00000000
						0x77ffc085 0x81f1f108 0x07077704 0x00000000
						0x0000003f 0x00000000 0x02000000 0x00000802
						0x00020000 0x00000100 0x0148000c 0x0148000c
						0x00000000 0x00000000 0x00000000 0x00000000
						0x80003012 0x1f7df7df 0x0000001f 0x0e00000b
						0x80000190 0x00000004 0x00000005 0x00000013
						0x0000000c 0x0000000f 0x00000002 0x00000003
						0x0000000c 0x00000002 0x00000002 0x00000006
						0x00000008 0x08060202 0x00160d13 0x72cc2414
						0x001f0000 0x00040000>;
				nvidia,emc-trimmers-0 = <0x00000000 0x00000006
						0x0000000a 0x00000008 0x00000006 0x007fc008
						0x0000000d 0x00000000 0x00000014 0x0028928a
						0x20820800 0x0000400a 0xa0f10f0f 0x00000000
						0x00001010 0x00000000 0x00000000 0x00000000
						0x00004008 0x00000008 0x007fc008 0x0000400a
						0x0000400a 0x0000400a 0x00000000 0x00000000
						0x00000000 0x00000000 0x00000000 0x00000000>;
				nvidia,emc-trimmers-1 = <0x00000000 0x00000006
						0x0000000a 0x00000008 0x00000006 0x00000008
						0x0000000d 0x00000000 0x00000014 0x0024a28a
						0x20820800 0x0000400a 0xa8f10f0f 0x00000000
						0x00000e0e 0x00000000 0x00000000 0x00000000
						0x007fc008 0x00000008 0x00000008 0x0000400a
						0x0000400a 0x0000400a 0x00000000 0x00000000
						0x00000000 0x00000000 0x00000000 0x00000000>;
				nvidia,emc-burst-up-down-regs = <0x00000196 0x00090009
						0x0009000a 0x000b000c 0x0000000c 0x000c000c
						0x0010000c 0x00000010 0x00100010 0x006d0033
						0x006d006d 0x4E564441 0x04010700 0x02000400
						792000>;
				nvidia,emc-zcal-cnt-long = <0x00000042>;
				nvidia,emc-acal-interval = <0x001fffff>;
				nvidia,emc-cfg = <0x53000000>;
				nvidia,emc-mode-reset = <0x80000d71>;
				nvidia,emc-mode-1 = <0x80100002>;
				nvidia,emc-mode-2 = <0x80200418>;
				nvidia,emc-mode-4 = <0x00000000>;
				nvidia,emc-clock-latency-change = <1200>;
			};
		};
		ram-code@1 { /* Hynix_1GB_H5TC2G63FFR-PBA */
			#address-cells = <1>;
			#size-cells = <0>;
			nvidia,ram-code = <1>;
			emc-table@12750 {
				compatible = "nvidia,tegra11-emc-table";
				reg = <12750>;
				clock-frequency = <12750>;
				nvidia,revision = <0x42>;
				nvidia,emc-min-mv = <900>;
				nvidia,source = "pll_p";
				nvidia,src-sel-reg = <0x4400003e>;
				nvidia,burst-regs-num = <100>;
				nvidia,emc-trimmers-num = <30>;
				nvidia,burst-up-down-regs-num = <11>;
				nvidia,emc-registers = <0x00000000 0x00000003
						0x00000000 0x00000000 0x00000000 0x00000004
						0x0000000a 0x00000003 0x0000000b 0x00000000
						0x00000000 0x00000003 0x00000001 0x00000000
						0x00000005 0x00000005 0x00000006 0x00010000
						0x00000000 0x00000004 0x0000000d 0x00000060
						0x00000000 0x00000018 0x00000002 0x00000002
						0x00000001 0x00000000 0x00000007 0x0000000f
						0x00000005 0x00000005 0x00000004 0x00000004
						0x00000004 0x00000001 0x00000000 0x00000004
						0x00000005 0x00000064 0x00000005 0x00000020
						0x00000000 0x0000aa88 0x002c00a0 0x00008000
						0x00048000 0x00048000 0x00048000 0x00048000
						0x00000000 0x00000000 0x00000000 0x00000000
						0x00000000 0x00000000 0x00000000 0x00000000
						0x001112a0 0x00000000 0x0000a11c 0x00000000
						0x77ffc085 0x81f1f108 0x03035504 0x0000003f
						0x0000003f 0x00000000 0x02000000 0x00000802
						0x00000000 0x00000042 0x000c000c 0x000c000c
						0x00000000 0x00000000 0x00000000 0x00000000
						0x800001c6 0x1f7df7df 0x0000001f 0x40040001
						0x8000003f 0x00000001 0x00000001 0x00000002
						0x00000000 0x00000001 0x00000001 0x00000002
						0x00000008 0x00000002 0x00000001 0x00000003
						0x00000006 0x06030102 0x000a0402 0x77e30303
						0x001f0000 0x00040320>;
				nvidia,emc-trimmers-0 = <0x00000000 0x00000006
						0x00000006 0x00000004 0x00000004 0x00048000
						0x00000009 0x00000000 0x0000000d 0x00208208
						0x20820800 0x00048000 0xa0f10000 0x00000000
						0x00000000 0x00000000 0x00000000 0x00000000
						0x00048000 0x00048000 0x00048000 0x00048000
						0x00048000 0x00048000 0x00000000 0x00000000
						0x00000000 0x00000000 0x00000000 0x00000000>;
				nvidia,emc-trimmers-1 = <0x00000000 0x00000006
						0x00000006 0x00000004 0x00000004 0x00048000
						0x00000009 0x00000000 0x0000000d 0x00208208
						0x20820800 0x00048000 0xa8f10000 0x00000000
						0x00000000 0x00000000 0x00000000 0x00000000
						0x00048000 0x00048000 0x00048000 0x00048000
						0x00048000 0x00048000 0x00000000 0x00000000
						0x00000000 0x00000000 0x00000000 0x00000000>;
				nvidia,emc-burst-up-down-regs = <0x00000007 0x00ff00ff
						0x00ff00ff 0x00ff00ff 0x000000ff 0x00ff00ff
						0x00ff00ff 0x000000ff 0x00ff00ff 0x00ff00ff
						0x00ff00ff 0x4E564441 0x04010700 0x02000400
						12750>;
				nvidia,emc-zcal-cnt-long = <0x00000042>;
				nvidia,emc-acal-interval = <0x001fffff>;
				nvidia,emc-cfg = <0x7320000e>;
				nvidia,emc-mode-reset = <0x80001221>;
				nvidia,emc-mode-1 = <0x80100003>;
				nvidia,emc-mode-2 = <0x80200008>;
				nvidia,emc-mode-4 = <0x00000000>;
				nvidia,emc-clock-latency-change = <57820>;
			};
			emc-table@20400 {
				compatible = "nvidia,tegra11-emc-table";
				reg = <20400>;
				clock-frequency = <20400>;
				nvidia,revision = <0x42>;
				nvidia,emc-min-mv = <900>;
				nvidia,source = "pll_p";
				nvidia,src-sel-reg = <0x44000026>;
				nvidia,burst-regs-num = <100>;
				nvidia,emc-trimmers-num = <30>;
				nvidia,burst-up-down-regs-num = <11>;
				nvidia,emc-registers = <0x00000000 0x00000003
						0x00000000 0x00000000 0x00000000 0x00000004
						0x0000000a 0x00000003 0x0000000b 0x00000000
						0x00000000 0x00000003 0x00000001 0x00000000
						0x00000005 0x00000005 0x00000006 0x00010000
						0x00000000 0x00000004 0x0000000d 0x0000009a
						0x00000000 0x00000026 0x00000002 0x00000002
						0x00000001 0x00000000 0x00000007 0x0000000f
						0x00000005 0x00000006 0x00000004 0x00000004
						0x00000004 0x00000001 0x00000000 0x00000004
						0x00000005 0x000000a0 0x00000005 0x00000020
						0x00000000 0x0000aa88 0x002c00a0 0x00008000
						0x00048000 0x00048000 0x00048000 0x00048000
						0x00000000 0x00000000 0x00000000 0x00000000
						0x00000000 0x00000000 0x00000000 0x00000000
						0x001112a0 0x00000000 0x0000a11c 0x00000000
						0x77ffc085 0x81f1f108 0x03035504 0x0000003f
						0x0000003f 0x00000000 0x02000000 0x00000802
						0x00000000 0x00000042 0x000c000c 0x000c000c
						0x00000000 0x00000000 0x00000000 0x00000000
						0x8000023a 0x1f7df7df 0x0000001f 0x40020001
						0x80000046 0x00000001 0x00000001 0x00000002
						0x00000000 0x00000001 0x00000001 0x00000002
						0x00000008 0x00000002 0x00000001 0x00000003
						0x00000006 0x06030102 0x000a0402 0x75430303
						0x001f0000 0x00040320>;
				nvidia,emc-trimmers-0 = <0x00000000 0x00000006
						0x00000006 0x00000004 0x00000004 0x00048000
						0x00000009 0x00000000 0x0000000d 0x00208208
						0x20820800 0x00048000 0xa0f10000 0x00000000
						0x00000000 0x00000000 0x00000000 0x00000000
						0x00048000 0x00048000 0x00048000 0x00048000
						0x00048000 0x00048000 0x00000000 0x00000000
						0x00000000 0x00000000 0x00000000 0x00000000>;
				nvidia,emc-trimmers-1 = <0x00000000 0x00000006
						0x00000006 0x00000004 0x00000004 0x00048000
						0x00000009 0x00000000 0x0000000d 0x00208208
						0x20820800 0x00048000 0xa8f10000 0x00000000
						0x00000000 0x00000000 0x00000000 0x00000000
						0x00048000 0x00048000 0x00048000 0x00048000
						0x00048000 0x00048000 0x00000000 0x00000000
						0x00000000 0x00000000 0x00000000 0x00000000>;
				nvidia,emc-burst-up-down-regs = <0x0000000a 0x00ff00ff
						0x00ff00ff 0x00ff00ff 0x000000ff 0x00ff00ff
						0x00ff00ff 0x000000ff 0x00ff00ff 0x00ff00ff
						0x00ff00ff 0x4E564441 0x04010700 0x02000400
						20400>;
				nvidia,emc-zcal-cnt-long = <0x00000042>;
				nvidia,emc-acal-interval = <0x001fffff>;
				nvidia,emc-cfg = <0x7320000e>;
				nvidia,emc-mode-reset = <0x80001221>;
				nvidia,emc-mode-1 = <0x80100003>;
				nvidia,emc-mode-2 = <0x80200008>;
				nvidia,emc-mode-4 = <0x00000000>;
				nvidia,emc-clock-latency-change = <35610>;
			};
			emc-table@40800 {
				compatible = "nvidia,tegra11-emc-table";
				reg = <40800>;
				clock-frequency = <40800>;
				nvidia,revision = <0x42>;
				nvidia,emc-min-mv = <900>;
				nvidia,source = "pll_p";
				nvidia,src-sel-reg = <0x44000012>;
				nvidia,burst-regs-num = <100>;
				nvidia,emc-trimmers-num = <30>;
				nvidia,burst-up-down-regs-num = <11>;
				nvidia,emc-registers = <0x00000001 0x00000005
						0x00000000 0x00000001 0x00000000 0x00000004
						0x0000000a 0x00000003 0x0000000b 0x00000000
						0x00000000 0x00000003 0x00000001 0x00000000
						0x00000005 0x00000005 0x00000006 0x00010000
						0x00000000 0x00000004 0x0000000d 0x00000134
						0x00000000 0x0000004d 0x00000002 0x00000002
						0x00000001 0x00000000 0x00000007 0x0000000f
						0x00000006 0x00000006 0x00000004 0x00000004
						0x00000004 0x00000002 0x00000000 0x00000004
						0x00000005 0x0000013f 0x00000005 0x00000020
						0x00000000 0x0000aa88 0x002c00a0 0x00008000
						0x00048000 0x00048000 0x00048000 0x00048000
						0x00000000 0x00000000 0x00000000 0x00000000
						0x00000000 0x00000000 0x00000000 0x00000000
						0x001112a0 0x00000000 0x0000a11c 0x00000000
						0x77ffc085 0x81f1f108 0x03035504 0x0000003f
						0x0000003f 0x00000000 0x02000000 0x00000802
						0x00000000 0x00000042 0x000c000c 0x000c000c
						0x00000000 0x00000000 0x00000000 0x00000000
						0x80000370 0x1f7df7df 0x0000001f 0xa0000001
						0x8000005b 0x00000001 0x00000001 0x00000002
						0x00000000 0x00000001 0x00000001 0x00000002
						0x00000008 0x00000002 0x00000001 0x00000003
						0x00000006 0x06030102 0x000a0402 0x73030303
						0x001f0000 0x00040320>;
				nvidia,emc-trimmers-0 = <0x00000000 0x00000006
						0x00000006 0x00000004 0x00000004 0x00048000
						0x00000009 0x00000000 0x0000000d 0x00208208
						0x20820800 0x00048000 0xa0f10000 0x00000000
						0x00000000 0x00000000 0x00000000 0x00000000
						0x00048000 0x00048000 0x00048000 0x00048000
						0x00048000 0x00048000 0x00000000 0x00000000
						0x00000000 0x00000000 0x00000000 0x00000000>;
				nvidia,emc-trimmers-1 = <0x00000000 0x00000006
						0x00000006 0x00000004 0x00000004 0x00048000
						0x00000009 0x00000000 0x0000000d 0x00208208
						0x20820800 0x00048000 0xa8f10000 0x00000000
						0x00000000 0x00000000 0x00000000 0x00000000
						0x00048000 0x00048000 0x00048000 0x00048000
						0x00048000 0x00048000 0x00000000 0x00000000
						0x00000000 0x00000000 0x00000000 0x00000000>;
				nvidia,emc-burst-up-down-regs = <0x00000015 0x00b000b0
						0x00b000c4 0x00d700eb 0x000000eb 0x00eb00eb
						0x00ff00eb 0x000000ff 0x00ff00ff 0x00ff00ff
						0x00ff00ff 0x4E564441 0x04010700 0x02000400
						40800>;
				nvidia,emc-zcal-cnt-long = <0x00000042>;
				nvidia,emc-acal-interval = <0x001fffff>;
				nvidia,emc-cfg = <0x7320000e>;
				nvidia,emc-mode-reset = <0x80001221>;
				nvidia,emc-mode-1 = <0x80100003>;
				nvidia,emc-mode-2 = <0x80200008>;
				nvidia,emc-mode-4 = <0x00000000>;
				nvidia,emc-clock-latency-change = <20850>;
			};
			emc-table@68000 {
				compatible = "nvidia,tegra11-emc-table";
				reg = <68000>;
				clock-frequency = <68000>;
				nvidia,revision = <0x42>;
				nvidia,emc-min-mv = <900>;
				nvidia,source = "pll_p";
				nvidia,src-sel-reg = <0x4400000a>;
				nvidia,burst-regs-num = <100>;
				nvidia,emc-trimmers-num = <30>;
				nvidia,burst-up-down-regs-num = <11>;
				nvidia,emc-registers = <0x00000003 0x00000008
						0x00000000 0x00000002 0x00000000 0x00000004
						0x0000000a 0x00000003 0x0000000b 0x00000000
						0x00000000 0x00000003 0x00000001 0x00000000
						0x00000005 0x00000005 0x00000006 0x00010000
						0x00000000 0x00000004 0x0000000d 0x00000202
						0x00000000 0x00000080 0x00000002 0x00000002
						0x00000001 0x00000000 0x00000007 0x0000000f
						0x0000000a 0x0000000a 0x00000004 0x00000004
						0x00000004 0x00000003 0x00000000 0x00000004
						0x00000005 0x00000213 0x00000005 0x00000020
						0x00000000 0x0000aa88 0x002c00a0 0x00008000
						0x00048000 0x00048000 0x00048000 0x00048000
						0x00000000 0x00000000 0x00000000 0x00000000
						0x00000000 0x00000000 0x00000000 0x00000000
						0x001112a0 0x00000000 0x0000a11c 0x00000000
						0x77ffc085 0x81f1f108 0x03035504 0x0000003f
						0x0000003f 0x00000000 0x02000000 0x00000802
						0x00000000 0x00000042 0x000c000c 0x000c000c
						0x00000000 0x00000000 0x00000000 0x00000000
						0x8000050e 0x1f7df7df 0x0000001f 0x00000001
						0x80000076 0x00000001 0x00000001 0x00000002
						0x00000000 0x00000001 0x00000001 0x00000002
						0x00000008 0x00000002 0x00000001 0x00000003
						0x00000006 0x06030102 0x000a0402 0x72630403
						0x001f0000 0x00040320>;
				nvidia,emc-trimmers-0 = <0x00000000 0x00000006
						0x00000006 0x00000004 0x00000004 0x00048000
						0x00000009 0x00000000 0x0000000d 0x00208208
						0x20820800 0x00048000 0xa0f10000 0x00000000
						0x00000000 0x00000000 0x00000000 0x00000000
						0x00048000 0x00048000 0x00048000 0x00048000
						0x00048000 0x00048000 0x00000000 0x00000000
						0x00000000 0x00000000 0x00000000 0x00000000>;
				nvidia,emc-trimmers-1 = <0x00000000 0x00000006
						0x00000006 0x00000004 0x00000004 0x00048000
						0x00000009 0x00000000 0x0000000d 0x00208208
						0x20820800 0x00048000 0xa8f10000 0x00000000
						0x00000000 0x00000000 0x00000000 0x00000000
						0x00048000 0x00048000 0x00048000 0x00048000
						0x00048000 0x00048000 0x00000000 0x00000000
						0x00000000 0x00000000 0x00000000 0x00000000>;
				nvidia,emc-burst-up-down-regs = <0x00000023 0x00690069
						0x00690075 0x0081008d 0x0000008d 0x008d008d
						0x00bc008d 0x000000bc 0x00bc00bc 0x00ff00ff
						0x00ff00ff 0x4E564441 0x04010700 0x02000400
						68000>;
				nvidia,emc-zcal-cnt-long = <0x00000042>;
				nvidia,emc-acal-interval = <0x001fffff>;
				nvidia,emc-cfg = <0x7320000e>;
				nvidia,emc-mode-reset = <0x80001221>;
				nvidia,emc-mode-1 = <0x80100003>;
				nvidia,emc-mode-2 = <0x80200008>;
				nvidia,emc-mode-4 = <0x00000000>;
				nvidia,emc-clock-latency-change = <10720>;
			};
			emc-table@102000 {
				compatible = "nvidia,tegra11-emc-table";
				reg = <102000>;
				clock-frequency = <102000>;
				nvidia,revision = <0x42>;
				nvidia,emc-min-mv = <900>;
				nvidia,source = "pll_p";
				nvidia,src-sel-reg = <0x44000006>;
				nvidia,burst-regs-num = <100>;
				nvidia,emc-trimmers-num = <30>;
				nvidia,burst-up-down-regs-num = <11>;
				nvidia,emc-registers = <0x00000004 0x0000000d
						0x00000000 0x00000003 0x00000001 0x00000004
						0x0000000a 0x00000003 0x0000000b 0x00000001
						0x00000001 0x00000003 0x00000001 0x00000000
						0x00000005 0x00000005 0x00000006 0x00010000
						0x00000000 0x00000004 0x0000000d 0x00000303
						0x00000000 0x000000c0 0x00000002 0x00000002
						0x00000001 0x00000000 0x0000000a 0x0000000f
						0x0000000f 0x0000000f 0x00000004 0x00000004
						0x00000004 0x00000005 0x00000000 0x00000004
						0x00000005 0x0000031c 0x00000005 0x00000020
						0x00000000 0x0000aa88 0x002c00a0 0x00008000
						0x00048000 0x00048000 0x00048000 0x00048000
						0x00000000 0x00000000 0x00000000 0x00000000
						0x00000000 0x00000000 0x00000000 0x00000000
						0x001112a0 0x00000000 0x0000a11c 0x00000000
						0x77ffc085 0x81f1f108 0x03035504 0x0000003f
						0x0000003f 0x00000000 0x02000000 0x00000802
						0x00000000 0x00000042 0x000c000c 0x000c000c
						0x00000000 0x00000000 0x00000000 0x00000000
						0x80000714 0x1f7df7df 0x0000001f 0x08000001
						0x80000098 0x00000001 0x00000001 0x00000003
						0x00000000 0x00000002 0x00000001 0x00000002
						0x00000008 0x00000002 0x00000001 0x00000003
						0x00000006 0x06030102 0x000a0403 0x72430504
						0x001f0000 0x00040320>;
				nvidia,emc-trimmers-0 = <0x00000000 0x00000006
						0x00000006 0x00000004 0x00000004 0x00048000
						0x00000009 0x00000000 0x0000000d 0x00208208
						0x20820800 0x00048000 0xa0f10000 0x00000000
						0x00000000 0x00000000 0x00000000 0x00000000
						0x00048000 0x00048000 0x00048000 0x00048000
						0x00048000 0x00048000 0x00000000 0x00000000
						0x00000000 0x00000000 0x00000000 0x00000000>;
				nvidia,emc-trimmers-1 = <0x00000000 0x00000006
						0x00000006 0x00000004 0x00000004 0x00048000
						0x00000009 0x00000000 0x0000000d 0x00208208
						0x20820800 0x00048000 0xa8f10000 0x00000000
						0x00000000 0x00000000 0x00000000 0x00000000
						0x00048000 0x00048000 0x00048000 0x00048000
						0x00048000 0x00048000 0x00000000 0x00000000
						0x00000000 0x00000000 0x00000000 0x00000000>;
				nvidia,emc-burst-up-down-regs = <0x00000034 0x00460046
						0x0046004e 0x0056005e 0x0000005e 0x005e005e
						0x007d005e 0x0000007d 0x007d007d 0x00ff00ff
						0x00ff00ff 0x4E564441 0x04010700 0x02000400
						102000>;
				nvidia,emc-zcal-cnt-long = <0x00000042>;
				nvidia,emc-acal-interval = <0x001fffff>;
				nvidia,emc-cfg = <0x7320000e>;
				nvidia,emc-mode-reset = <0x80001221>;
				nvidia,emc-mode-1 = <0x80100003>;
				nvidia,emc-mode-2 = <0x80200008>;
				nvidia,emc-mode-4 = <0x00000000>;
				nvidia,emc-clock-latency-change = <6890>;
			};
			emc-table@204000 {
				compatible = "nvidia,tegra11-emc-table";
				reg = <204000>;
				clock-frequency = <204000>;
				nvidia,revision = <0x42>;
				nvidia,emc-min-mv = <900>;
				nvidia,source = "pll_p";
				nvidia,src-sel-reg = <0x44000002>;
				nvidia,burst-regs-num = <100>;
				nvidia,emc-trimmers-num = <30>;
				nvidia,burst-up-down-regs-num = <11>;
				nvidia,emc-registers = <0x00000009 0x0000001a
						0x00000000 0x00000007 0x00000002 0x00000004
						0x0000000a 0x00000003 0x0000000b 0x00000002
						0x00000002 0x00000003 0x00000001 0x00000000
						0x00000005 0x00000005 0x00000006 0x00010000
						0x00000000 0x00000004 0x0000000d 0x00000607
						0x00000000 0x00000181 0x00000002 0x00000002
						0x00000001 0x00000000 0x00000017 0x0000000f
						0x0000001d 0x0000001d 0x00000004 0x00000004
						0x00000004 0x00000009 0x00000000 0x00000004
						0x00000005 0x00000638 0x00000006 0x00000020
						0x00000000 0x0000aa88 0x000000a0 0x00008000
						0x00048000 0x00048000 0x00048000 0x00048000
						0x00000000 0x00000000 0x00000000 0x00000000
						0x00000000 0x00000000 0x00000000 0x00000000
						0x001112a0 0x00000000 0x0000a11c 0x00000000
						0x77ffc085 0x81f1f108 0x05057404 0x0000003f
						0x0000003f 0x00000000 0x02000000 0x00000802
						0x00020000 0x00000100 0x000c000c 0x000c000c
						0x00000000 0x00000000 0x00000000 0x00000000
						0x80000d22 0x1f7df7df 0x0000001f 0x01000003
						0x800000fe 0x00000001 0x00000001 0x00000005
						0x00000002 0x00000004 0x00000001 0x00000002
						0x00000008 0x00000002 0x00000001 0x00000003
						0x00000006 0x06030102 0x000a0405 0x71e40a06
						0x001f0000 0x00040320>;
				nvidia,emc-trimmers-0 = <0x00000000 0x00000004
						0x00000007 0x00000004 0x00000004 0x00048000
						0x00000009 0x00000000 0x0000000d 0x0079e79e
						0x20820800 0x00048000 0xa0f10000 0x00000000
						0x00000808 0x00000000 0x00000000 0x00000000
						0x00048000 0x00048000 0x00048000 0x00048000
						0x00048000 0x00048000 0x00000000 0x00000000
						0x00000000 0x00000000 0x00000000 0x00000000>;
				nvidia,emc-trimmers-1 = <0x00000000 0x00000004
						0x00000007 0x00000004 0x00000004 0x00048000
						0x00000009 0x00000000 0x0000000d 0x0079e79e
						0x20820800 0x00048000 0xa8f10000 0x00000000
						0x00000808 0x00000000 0x00000000 0x00000000
						0x00048000 0x00048000 0x00048000 0x00048000
						0x00048000 0x00048000 0x00000000 0x00000000
						0x00000000 0x00000000 0x00000000 0x00000000>;
				nvidia,emc-burst-up-down-regs = <0x00000068 0x00230023
						0x00230027 0x002b002f 0x0000002f 0x002f002f
						0x003e002f 0x0000003e 0x003e003e 0x00ff00c8
						0x00ff00ff 0x4E564441 0x04010700 0x02000400
						204000>;
				nvidia,emc-zcal-cnt-long = <0x00000042>;
				nvidia,emc-acal-interval = <0x001fffff>;
				nvidia,emc-cfg = <0x7320000e>;
				nvidia,emc-mode-reset = <0x80001221>;
				nvidia,emc-mode-1 = <0x80100003>;
				nvidia,emc-mode-2 = <0x80200008>;
				nvidia,emc-mode-4 = <0x00000000>;
				nvidia,emc-clock-latency-change = <3420>;
			};
			emc-table@312000 {
				compatible = "nvidia,tegra11-emc-table";
				reg = <312000>;
				clock-frequency = <312000>;
				nvidia,revision = <0x42>;
				nvidia,emc-min-mv = <1000>;
				nvidia,source = "pll_c";
				nvidia,src-sel-reg = <0x24000002>;
				nvidia,burst-regs-num = <100>;
				nvidia,emc-trimmers-num = <30>;
				nvidia,burst-up-down-regs-num = <11>;
				nvidia,emc-registers = <0x0000000e 0x00000026
						0x00000000 0x00000009 0x00000003 0x00000004
						0x00000008 0x00000002 0x00000009 0x00000003
						0x00000003 0x00000002 0x00000001 0x00000000
						0x00000004 0x00000004 0x00000007 0x00080006
						0x00000000 0x00000004 0x0000000d 0x00000945
						0x00000000 0x00000251 0x00000001 0x00000008
						0x00000001 0x00000000 0x00000024 0x0000000e
						0x0000002c 0x00000200 0x00000004 0x00000004
						0x00000004 0x0000000d 0x00000000 0x00000004
						0x00000005 0x00000986 0x00000006 0x00000020
						0x00000000 0x0000ba88 0x002c00a0 0x00008000
						0x00028000 0x00028000 0x00028000 0x00028000
						0x00028000 0x00028000 0x00028000 0x00028000
						0x00000000 0x00000000 0x00000000 0x00000000
						0x001112a0 0x00000000 0x0001013d 0x00000000
						0x77ffc085 0x81f1f108 0x03037504 0x00000000
						0x0000003f 0x00000000 0x02000000 0x00000802
						0x00020000 0x00000100 0x019a000c 0x019a000c
						0x00000000 0x00000000 0x00000000 0x00000000
						0x80001395 0x1f7df7df 0x0000001f 0x0b000004
						0x8000016a 0x00000001 0x00000002 0x00000007
						0x00000004 0x00000006 0x00000001 0x00000002
						0x00000007 0x00000002 0x00000002 0x00000004
						0x00000006 0x06040202 0x000b0607 0x76e50f08
						0x001f0000 0x00040320>;
				nvidia,emc-trimmers-0 = <0x00000000 0x00000004
						0x00000007 0x00000005 0x00000004 0x00028000
						0x0000000b 0x00028000 0x0000000d 0x00208208
						0x10410400 0x00028000 0xa0f10000 0x00024000
						0x00000000 0x00000000 0x00024000 0x00024000
						0x00028000 0x00028000 0x00028000 0x00028000
						0x00028000 0x00028000 0x00000000 0x00000000
						0x00000000 0x00028000 0x00028000 0x00028000>;
				nvidia,emc-trimmers-1 = <0x00000000 0x00000004
						0x00000007 0x00000005 0x00000004 0x00028000
						0x0000000b 0x00028000 0x0000000d 0x00208208
						0x10410400 0x00028000 0xa8f10000 0x00024000
						0x00000000 0x00000000 0x00024000 0x00024000
						0x00028000 0x00028000 0x00028000 0x00028000
						0x00028000 0x00028000 0x00000000 0x00000000
						0x00000000 0x00028000 0x00028000 0x00028000>;
				nvidia,emc-burst-up-down-regs = <0x000000a0 0x00170017
						0x00170019 0x001c001e 0x0000001e 0x001e001e
						0x0029001e 0x00000029 0x00290029 0x00ff0082
						0x00ff00ff 0x4E564441 0x04010700 0x02000400
						312000>;
				nvidia,emc-zcal-cnt-long = <0x00000042>;
				nvidia,emc-acal-interval = <0x001fffff>;
				nvidia,emc-cfg = <0x5300000e>;
				nvidia,emc-mode-reset = <0x80000321>;
				nvidia,emc-mode-1 = <0x80100002>;
				nvidia,emc-mode-2 = <0x80200000>;
				nvidia,emc-mode-4 = <0x00000000>;
				nvidia,emc-clock-latency-change = <2180>;
			};
			emc-table@408000 {
				compatible = "nvidia,tegra11-emc-table";
				reg = <408000>;
				clock-frequency = <408000>;
				nvidia,revision = <0x42>;
				nvidia,emc-min-mv = <1000>;
				nvidia,source = "pll_p";
				nvidia,src-sel-reg = <0x44000000>;
				nvidia,burst-regs-num = <100>;
				nvidia,emc-trimmers-num = <30>;
				nvidia,burst-up-down-regs-num = <11>;
				nvidia,emc-registers = <0x00000012 0x00000033
						0x00000000 0x0000000d 0x00000004 0x00000005
						0x00000009 0x00000002 0x0000000c 0x00000004
						0x00000004 0x00000002 0x00000001 0x00000000
						0x00000004 0x00000004 0x00000007 0x00080006
						0x00000000 0x00000004 0x0000000e 0x00000c2f
						0x00000000 0x0000030b 0x00000001 0x00000008
						0x00000001 0x00000000 0x00000030 0x00000011
						0x00000039 0x00000200 0x00000004 0x00000004
						0x00000004 0x00000011 0x00000000 0x00000004
						0x00000005 0x00000c70 0x00000006 0x00000020
						0x00000000 0x0000ba88 0x002c0080 0x00008000
						0x0001c000 0x0001c000 0x0001c000 0x0001c000
						0x00000000 0x00000000 0x00000000 0x00000000
						0x00000000 0x00000000 0x00000000 0x00000000
						0x001112a0 0x00000000 0x0001013d 0x00000000
						0x77ffc085 0x81f1f108 0x03037504 0x00000000
						0x0000003f 0x00000000 0x02000000 0x00000802
						0x00020000 0x00000100 0x018e000c 0x018e000c
						0x00000000 0x00000000 0x00000000 0x00000000
						0x80001944 0x1f7df7df 0x0000001f 0x02000006
						0x80000190 0x00000001 0x00000002 0x0000000a
						0x00000006 0x00000008 0x00000001 0x00000002
						0x00000009 0x00000002 0x00000002 0x00000004
						0x00000006 0x06040202 0x000e070a 0x7547130b
						0x001f0000 0x00040320>;
				nvidia,emc-trimmers-0 = <0x00000000 0x00000004
						0x00000007 0x00000005 0x00000004 0x0001c000
						0x0000000c 0x00000000 0x0000000e 0x00208208
						0x10410400 0x0001c000 0xa0f10000 0x00000005
						0x00000000 0x00000000 0x00000005 0x00000005
						0x0001c000 0x0001c000 0x0001c000 0x0001c000
						0x0001c000 0x0001c000 0x00000000 0x00000000
						0x00000000 0x00000000 0x00000000 0x00000000>;
				nvidia,emc-trimmers-1 = <0x00000000 0x00000004
						0x00000007 0x00000005 0x00000004 0x0001c000
						0x0000000c 0x00000000 0x0000000e 0x00208208
						0x10410400 0x0001c000 0xa8f10000 0x00000005
						0x00000000 0x00000000 0x00000005 0x00000005
						0x0001c000 0x0001c000 0x0001c000 0x0001c000
						0x0001c000 0x0001c000 0x00000000 0x00000000
						0x00000000 0x00000000 0x00000000 0x00000000>;
				nvidia,emc-burst-up-down-regs = <0x000000d1 0x00110011
						0x00110013 0x00150017 0x00000017 0x00170017
						0x001f0017 0x0000001f 0x001f001f 0x00d30064
						0x00d300d3 0x4E564441 0x04010700 0x02000400
						408000>;
				nvidia,emc-zcal-cnt-long = <0x00000042>;
				nvidia,emc-acal-interval = <0x001fffff>;
				nvidia,emc-cfg = <0x53000006>;
				nvidia,emc-mode-reset = <0x80000731>;
				nvidia,emc-mode-1 = <0x80100002>;
				nvidia,emc-mode-2 = <0x80200008>;
				nvidia,emc-mode-4 = <0x00000000>;
				nvidia,emc-clock-latency-change = <1750>;
			};
			emc-table@624000 {
				compatible = "nvidia,tegra11-emc-table";
				reg = <624000>;
				clock-frequency = <624000>;
				nvidia,revision = <0x42>;
				nvidia,emc-min-mv = <1100>;
				nvidia,source = "pll_c";
				nvidia,src-sel-reg = <0x24000000>;
				nvidia,burst-regs-num = <100>;
				nvidia,emc-trimmers-num = <30>;
				nvidia,burst-up-down-regs-num = <11>;
				nvidia,emc-registers = <0x0000001d 0x0000004e
						0x00000000 0x00000014 0x00000007 0x00000007
						0x0000000b 0x00000003 0x00000010 0x00000007
						0x00000007 0x00000003 0x00000001 0x00000000
						0x00000005 0x00000005 0x0000000a 0x00010000
						0x00000000 0x00000007 0x00000012 0x000012c4
						0x00000000 0x000004b1 0x00000002 0x0000000d
						0x00000001 0x00000000 0x00000049 0x00000015
						0x00000057 0x00000200 0x00000005 0x00000005
						0x00000005 0x00000019 0x00000000 0x00000006
						0x00000007 0x00001305 0x00000009 0x80000000
						0x00000000 0x0000ba88 0xf00d0191 0x00008000
						0x007f800b 0x007f800b 0x007f800b 0x007f800b
						0x00000000 0x00000000 0x00000000 0x00000000
						0x00000000 0x00000000 0x00000000 0x00000000
						0x001112a0 0x00000000 0x0000013d 0x00000000
						0x77ffc085 0x81f1f108 0x07077504 0x00000000
						0x0000003f 0x00000000 0x02000000 0x00000802
						0x00020000 0x00000100 0x0175000c 0x0175000c
						0x00000000 0x00000000 0x00000000 0x00000000
						0x8000261a 0x1f7df7df 0x0000001f 0x06000009
						0x80000190 0x00000003 0x00000004 0x0000000f
						0x00000009 0x0000000c 0x00000001 0x00000003
						0x0000000b 0x00000002 0x00000002 0x00000005
						0x00000007 0x07050202 0x00130b0f 0x736a1d10
						0x001f0000 0x00040320>;
				nvidia,emc-trimmers-0 = <0x00000000 0x00000006
						0x0000000a 0x00000008 0x00000004 0x007f800b
						0x0000000c 0x00000000 0x00000012 0x0028a28a
						0x10410400 0x00000009 0xa0f10000 0x007f800d
						0x00000909 0x00000000 0x007f800d 0x007f800d
						0x007f800b 0x007f800b 0x007f800b 0x00000009
						0x00000009 0x00000009 0x00000000 0x00000000
						0x00000000 0x00000000 0x00000000 0x00000000>;
				nvidia,emc-trimmers-1 = <0x00000000 0x00000006
						0x0000000a 0x00000008 0x00000004 0x007f800b
						0x0000000c 0x00000000 0x00000012 0x0028a28a
						0x10410400 0x00000009 0xa8f10000 0x007f800d
						0x00000909 0x00000000 0x007f800d 0x007f800d
						0x007f800b 0x007f800b 0x007f800b 0x00000009
						0x00000009 0x00000009 0x00000000 0x00000000
						0x00000000 0x00000000 0x00000000 0x00000000>;
				nvidia,emc-burst-up-down-regs = <0x0000013f 0x000b000b
						0x000b000c 0x000e000f 0x0000000f 0x000f000f
						0x0014000f 0x00000014 0x00140014 0x008a0041
						0x008a008a 0x4E564441 0x04010700 0x02000400
						624000>;
				nvidia,emc-zcal-cnt-long = <0x00000042>;
				nvidia,emc-acal-interval = <0x001fffff>;
				nvidia,emc-cfg = <0x53200000>;
				nvidia,emc-mode-reset = <0x80000b61>;
				nvidia,emc-mode-1 = <0x80100002>;
				nvidia,emc-mode-2 = <0x80200410>;
				nvidia,emc-mode-4 = <0x00000000>;
				nvidia,emc-clock-latency-change = <1290>;
			};
			emc-table@792000 {
				compatible = "nvidia,tegra11-emc-table";
				reg = <792000>;
				clock-frequency = <792000>;
				nvidia,revision = <0x42>;
				nvidia,emc-min-mv = <1100>;
				nvidia,source = "pll_m";
				nvidia,src-sel-reg = <0x84000000>;
				nvidia,burst-regs-num = <100>;
				nvidia,emc-trimmers-num = <30>;
				nvidia,burst-up-down-regs-num = <11>;
				nvidia,emc-registers = <0x00000024 0x00000064
						0x00000000 0x00000019 0x0000000a 0x00000009
						0x0000000d 0x00000004 0x00000013 0x0000000a
						0x0000000a 0x00000004 0x00000001 0x00000000
						0x00000006 0x00000006 0x0000000b 0x000d000a
						0x00000000 0x00000008 0x00000014 0x000017e4
						0x00000000 0x000005f9 0x00000003 0x00000012
						0x00000001 0x00000000 0x0000005d 0x00000018
						0x0000006e 0x00000200 0x00000005 0x00000005
						0x00000005 0x00000020 0x00000000 0x00000007
						0x00000008 0x00001825 0x0000000a 0x80000020
						0x00000000 0x0000ba88 0xf0070191 0x00008000
						0x00000008 0x00000008 0x00000008 0x00000008
						0x00000000 0x00000000 0x00000000 0x00000000
						0x00000000 0x00000000 0x00000000 0x00000000
						0x001112a0 0x00000000 0x0000013d 0x00000000
						0x77ffc084 0x81f1f508 0x07077604 0x00000000
						0x0000003f 0x00000000 0x02000000 0x00000802
						0x00020000 0x00000100 0x0161000c 0x0161000c
						0x20200000 0x00000000 0x00000000 0x00000000
						0x80003018 0x1f7df7df 0x0000001f 0x0e00000b
						0x80000190 0x00000004 0x00000005 0x00000013
						0x0000000c 0x0000000f 0x00000002 0x00000003
						0x0000000c 0x00000002 0x00000002 0x00000006
						0x00000008 0x08060202 0x00170e13 0x72cc2414
						0x001f0000 0x00040000>;
				nvidia,emc-trimmers-0 = <0x00000000 0x00000006
						0x0000000b 0x00000008 0x00000006 0x00000008
						0x0000000d 0x00000000 0x00000014 0x0028a28a
						0x10410400 0x0000400a 0xa0f10f0f 0x007f800e
						0x00000b0b 0x00000000 0x007f800e 0x007f800e
						0x00000008 0x00000008 0x00000008 0x0000400a
						0x0000400a 0x0000400a 0x00000000 0x00000000
						0x00000000 0x00000000 0x00000000 0x00000000>;
				nvidia,emc-trimmers-1 = <0x00000000 0x00000006
						0x0000000b 0x00000008 0x00000006 0x00000008
						0x0000000d 0x00000000 0x00000014 0x0028a28a
						0x10410400 0x0000400a 0xa8f10f0f 0x007f800e
						0x00000b0b 0x00000000 0x007f800e 0x007f800e
						0x00000008 0x00000008 0x00000008 0x0000400a
						0x0000400a 0x0000400a 0x00000000 0x00000000
						0x00000000 0x00000000 0x00000000 0x00000000>;
				nvidia,emc-burst-up-down-regs = <0x00000196 0x00090009
						0x0009000a 0x000b000c 0x0000000c 0x000c000c
						0x0010000c 0x00000010 0x00100010 0x006d0033
						0x006d006d 0x4E564441 0x04010700 0x02000400
						792000>;
				nvidia,emc-zcal-cnt-long = <0x00000042>;
				nvidia,emc-acal-interval = <0x001fffff>;
				nvidia,emc-cfg = <0x53000000>;
				nvidia,emc-mode-reset = <0x80000d71>;
				nvidia,emc-mode-1 = <0x80100002>;
				nvidia,emc-mode-2 = <0x80200218>;
				nvidia,emc-mode-4 = <0x00000000>;
				nvidia,emc-clock-latency-change = <1200>;
			};
		};
	};

	mipical {
		compatible = "nvidia,tegra114-mipical";
		reg = <0x700e3000 0x00040000>;
	};
};
